VERSION "HSCAN6"

NS_ :

BS_:

BU_: Merged DBC

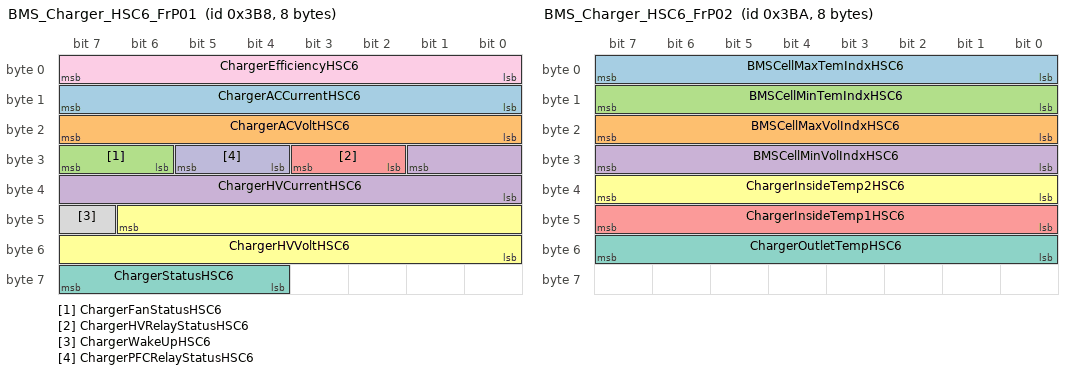
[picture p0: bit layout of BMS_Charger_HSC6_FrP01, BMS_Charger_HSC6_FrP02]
BO_ 952 BMS_Charger_HSC6_FrP01: 8 BMS
 SG_ ChargerACCurrentHSC6 : 15|8@0+ (0.2,0) [0|50.8] "A"  vector__xxx
 SG_ ChargerACVoltHSC6 : 23|8@0+ (2,0) [0|508] "V"  vector__xxx
 SG_ ChargerFanStatusHSC6 : 31|2@0+ (1,0) [0|3] ""  vector__xxx
 SG_ ChargerHVCurrentHSC6 : 25|10@0+ (0.02,0) [0|20.44] "A"  vector__xxx
 SG_ ChargerHVRelayStatusHSC6 : 27|2@0+ (1,0) [0|3] ""  vector__xxx
 SG_ ChargerHVVoltHSC6 : 46|15@0+ (0.02,0) [0|655.32] "V"  vector__xxx
 SG_ ChargerStatusHSC6 : 63|4@0+ (1,0) [0|15] ""  Telematics_BOX
 SG_ ChargerWakeUpHSC6 : 47|1@0+ (1,0) [0|1] ""  vector__xxx
 SG_ ChargerEfficiencyHSC6 : 7|8@0+ (0.5,0) [0|127] "%"  Tester
 SG_ ChargerPFCRelayStatusHSC6 : 29|2@0+ (1,0) [0|3] ""  vector__xxx

BO_ 954 BMS_Charger_HSC6_FrP02: 8 BMS
 SG_ BMSCellMaxTemIndxHSC6 : 7|8@0+ (1,0) [0|254] ""  Telematics_BOX
 SG_ BMSCellMaxVolIndxHSC6 : 23|8@0+ (1,0) [0|254] ""  Telematics_BOX
 SG_ BMSCellMinTemIndxHSC6 : 15|8@0+ (1,0) [0|254] ""  Telematics_BOX
 SG_ BMSCellMinVolIndxHSC6 : 31|8@0+ (1,0) [0|254] ""  Telematics_BOX
 SG_ ChargerInsideTemp1HSC6 : 47|8@0+ (1,-40) [-40|214] "DegC"  vector__xxx
 SG_ ChargerInsideTemp2HSC6 : 39|8@0+ (1,-40) [-40|214] "DegC"  vector__xxx
 SG_ ChargerOutletTempHSC6 : 55|8@0+ (1,-40) [-40|214] "DegC"  vector__xxx

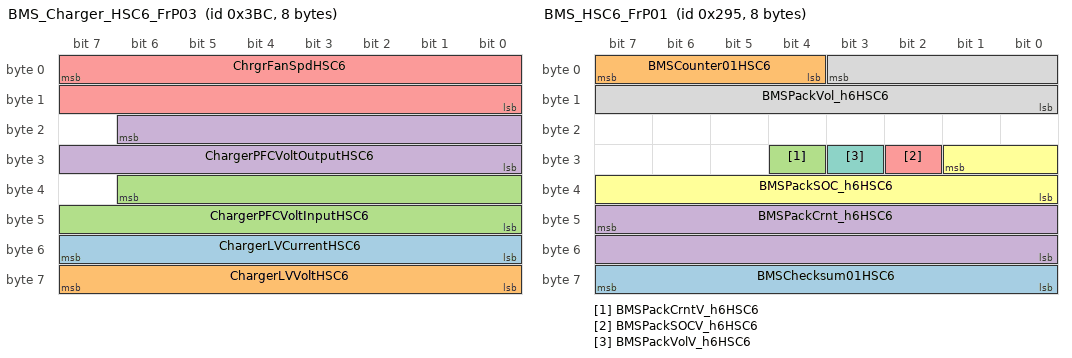
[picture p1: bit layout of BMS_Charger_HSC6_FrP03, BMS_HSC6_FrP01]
BO_ 956 BMS_Charger_HSC6_FrP03: 8 BMS
 SG_ ChargerLVCurrentHSC6 : 55|8@0+ (0.1,0) [0|25.4] "A"  vector__xxx
 SG_ ChargerLVVoltHSC6 : 63|8@0+ (0.1,0) [0|25.4] "V"  vector__xxx
 SG_ ChargerPFCVoltInputHSC6 : 38|15@0+ (0.02,0) [0|655.32] "V"  vector__xxx
 SG_ ChargerPFCVoltOutputHSC6 : 22|15@0+ (0.02,0) [0|655.32] "V"  vector__xxx
 SG_ ChrgrFanSpdHSC6 : 7|16@0+ (1,0) [0|65535] "r/s"  vector__xxx

BO_ 958 BMS_Charger_HSC6_FrP04: 8 BMS
 SG_ BMSCellTemHSC6 : 15|8@0+ (1,-40) [-40|215] "¡æ"  Telematics_BOX
 SG_ BMSCellTemIndxHSC6 : 39|8@0+ (1,0) [0|254] ""  Telematics_BOX
 SG_ BMSCellTemVHSC6 : 7|1@0+ (1,0) [0|1] ""  Telematics_BOX
 SG_ BMSCellVolHSC6 : 19|12@0+ (0.001,1) [1|5.095] "V"  Telematics_BOX
 SG_ BMSCellVolIndxHSC6 : 47|8@0+ (1,0) [0|254] ""  Telematics_BOX
 SG_ BMSCellVolVHSC6 : 6|1@0+ (1,0) [0|1] ""  Telematics_BOX
 SG_ Charger12VUVHSC6 : 5|1@0+ (1,0) [0|1] ""  vector__xxx
 SG_ ChargerBatteryReverseHSC6 : 4|1@0+ (1,0) [0|1] ""  vector__xxx
 SG_ ChargerCANMissingHSC6 : 22|1@0+ (1,0) [0|1] ""  vector__xxx
 SG_ ChargerHVOVHSC6 : 3|1@0+ (1,0) [0|1] ""  vector__xxx
 SG_ ChargerHVUVHSC6 : 2|1@0+ (1,0) [0|1] ""  vector__xxx
 SG_ ChargerInletTempOTPHSC6 : 1|1@0+ (1,0) [0|1] ""  vector__xxx
 SG_ ChargerInsideTemp1OTPHSC6 : 0|1@0+ (1,0) [0|1] ""  vector__xxx
 SG_ ChargerVinUVHSC6 : 23|1@0+ (1,0) [0|1] ""  vector__xxx
 SG_ ChrgrAltCrntLmtHSC6 : 31|8@0+ (0.5,0) [0|127] "A"  vector__xxx
 SG_ ChrgrPriySideStwrOverCHSC6 : 20|1@0+ (1,0) [0|1] ""  vector__xxx

BO_ 659 BMS_HSC6_FrP00: 8 BMS
 SG_ BMSBalancingDoneHSC6 : 18|1@0+ (1,0) [0|1] ""  Tester
 SG_ BMSBalancingStatusHSC6 : 24|1@0+ (1,0) [0|1] ""  Telematics_BOX,Tester
 SG_ BMSCellBalancingCountHSC6 : 15|8@0+ (1,0) [0|253] ""  Tester
 SG_ BMSCellOverVoltHSC6 : 39|1@0+ (1,0) [0|1] ""  Tester
 SG_ BMSCellUnderVoltHSC6 : 19|1@0+ (1,0) [0|1] ""  Tester
 SG_ BMSContactorPowerCmdHSC6 : 16|1@0+ (1,0) [0|1] ""  Tester
 SG_ BMSContactorPowerMonHSC6 : 25|1@0+ (1,0) [0|1] ""  Tester
 SG_ BMSCrashCircuitStatusHSC6 : 17|1@0+ (1,0) [0|1] ""  Tester
 SG_ BMSEEpromWipHSC6 : 38|1@0+ (1,0) [0|1] ""  Tester
 SG_ BMSLVBatInputHSC6 : 7|8@0+ (0.1,0) [0|25.3] "V"  Telematics_BOX,Tester
 SG_ BMSModuleEnableHSC6 : 27|1@0+ (1,0) [0|1] ""  Tester
 SG_ BMSNegRelayStatusHSC6 : 47|2@0+ (1,0) [0|3] ""  Telematics_BOX,Tester
 SG_ BMSOffbdChargerWakeupHSC6 : 30|1@0+ (1,0) [0|1] ""  Tester
 SG_ BMSOnbdChargerWakeupHSC6 : 28|1@0+ (1,0) [0|1] ""  Tester
 SG_ BMSPosRelayStatusHSC6 : 33|2@0+ (1,0) [0|3] ""  Telematics_BOX,Tester
 SG_ BMSPreRelayStatusHSC6 : 35|2@0+ (1,0) [0|3] ""  Telematics_BOX,Tester
 SG_ BMSPTIsolationLevelHSC6 : 37|2@0+ (1,0) [0|3] ""  Tester
 SG_ BMSReadyHSC6 : 26|1@0+ (1,0) [0|1] ""  Tester
 SG_ BMSRelayStepHSC6 : 23|4@0+ (1,0) [0|15] ""  Telematics_BOX,Tester
 SG_ BMSVehicleWakeupHSC6 : 29|1@0+ (1,0) [0|1] ""  Telematics_BOX,Tester
 SG_ BMSChgRelayStatusHSC6 : 45|2@0+ (1,0) [0|3] ""  Tester,Telematics_BOX
 SG_ BMSOffbdChargerPlugOnHSC6 : 31|1@0+ (1,0) [0|1] ""  Tester

BO_ 661 BMS_HSC6_FrP01: 8 BMS
 SG_ BMSChecksum01HSC6 : 63|8@0+ (1,0) [0|0] ""  HCU
 SG_ BMSCounter01HSC6 : 7|4@0+ (1,0) [0|15] "count value"  HCU
 SG_ BMSPackCrntV_h6HSC6 : 28|1@0+ (1,0) [0|1] ""  Telematics_BOX,HCU,TC
 SG_ BMSPackCrnt_h6HSC6 : 47|16@0+ (0.025,-1000) [-1000|638.375] "A"  Telematics_BOX,HCU,TC
 SG_ BMSPackSOCV_h6HSC6 : 26|1@0+ (1,0) [0|1] ""  Telematics_BOX,HCU,TC
 SG_ BMSPackSOC_h6HSC6 : 25|10@0+ (0.1,0) [0|102.3] "%"  Telematics_BOX,HCU,TC
 SG_ BMSPackVolV_h6HSC6 : 27|1@0+ (1,0) [0|1] ""  Telematics_BOX,HCU,TC
 SG_ BMSPackVol_h6HSC6 : 3|12@0+ (0.25,0) [0|1023.75] "V"  Telematics_BOX,HCU,TC

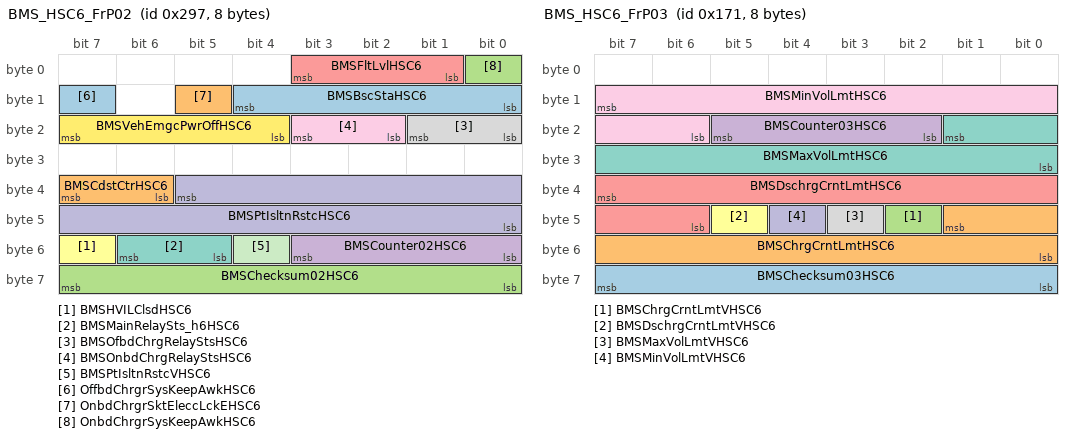
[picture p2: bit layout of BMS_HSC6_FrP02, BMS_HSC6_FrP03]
BO_ 663 BMS_HSC6_FrP02: 8 BMS
 SG_ BMSBscStaHSC6 : 12|5@0+ (1,0) [0|31] ""  Telematics_BOX,HCU,TC
 SG_ BMSCdstCtrHSC6 : 39|2@0+ (1,0) [0|3] ""  Telematics_BOX,HCU
 SG_ BMSChecksum02HSC6 : 63|8@0+ (1,0) [0|0] ""  HCU
 SG_ BMSCounter02HSC6 : 51|4@0+ (1,0) [0|15] "count value"  HCU,TC
 SG_ BMSFltLvlHSC6 : 3|3@0+ (1,0) [0|7] ""  Telematics_BOX,HCU
 SG_ BMSHVILClsdHSC6 : 55|1@0+ (1,0) [0|1] ""  Telematics_BOX,HCU
 SG_ BMSMainRelaySts_h6HSC6 : 54|2@0+ (1,0) [0|3] ""  Telematics_BOX,HCU,TC
 SG_ BMSOfbdChrgRelayStsHSC6 : 17|2@0+ (1,0) [0|3] ""  vector__xxx
 SG_ BMSOnbdChrgRelayStsHSC6 : 19|2@0+ (1,0) [0|3] ""  vector__xxx
 SG_ BMSPtIsltnRstcHSC6 : 37|14@0+ (0.5,0) [0|8191.5] "kOhm"  Telematics_BOX,HCU
 SG_ BMSPtIsltnRstcVHSC6 : 52|1@0+ (1,0) [0|1] ""  Telematics_BOX,HCU
 SG_ BMSVehEmgcPwrOffHSC6 : 23|4@0+ (1,0) [0|15] ""  Tester
 SG_ OffbdChrgrSysKeepAwkHSC6 : 15|1@0+ (1,0) [0|1] ""  Telematics_BOX,HCU
 SG_ OnbdChrgrSktEleccLckEHSC6 : 13|1@0+ (1,0) [0|1] ""  HCU
 SG_ OnbdChrgrSysKeepAwkHSC6 : 0|1@0+ (1,0) [0|1] ""  Telematics_BOX,HCU

BO_ 369 BMS_HSC6_FrP03: 8 BMS
 SG_ BMSChecksum03HSC6 : 63|8@0+ (1,0) [0|0] ""  TC
 SG_ BMSChrgCrntLmtHSC6 : 41|10@0+ (1,-1023) [-1023|0] "A"  HCU,TC
 SG_ BMSChrgCrntLmtVHSC6 : 42|1@0+ (1,0) [0|1] ""  HCU,TC
 SG_ BMSCounter03HSC6 : 21|4@0+ (1,0) [0|15] "count value"  TC
 SG_ BMSDschrgCrntLmtHSC6 : 39|10@0+ (1,0) [0|1023] "A"  HCU,TC
 SG_ BMSDschrgCrntLmtVHSC6 : 45|1@0+ (1,0) [0|1] ""  HCU,TC
 SG_ BMSMaxVolLmtHSC6 : 17|10@0+ (1,0) [0|1023] "V"  TC
 SG_ BMSMaxVolLmtVHSC6 : 43|1@0+ (1,0) [0|1] ""  TC
 SG_ BMSMinVolLmtHSC6 : 15|10@0+ (1,0) [0|1023] "V"  TC
 SG_ BMSMinVolLmtVHSC6 : 44|1@0+ (1,0) [0|1] ""  TC

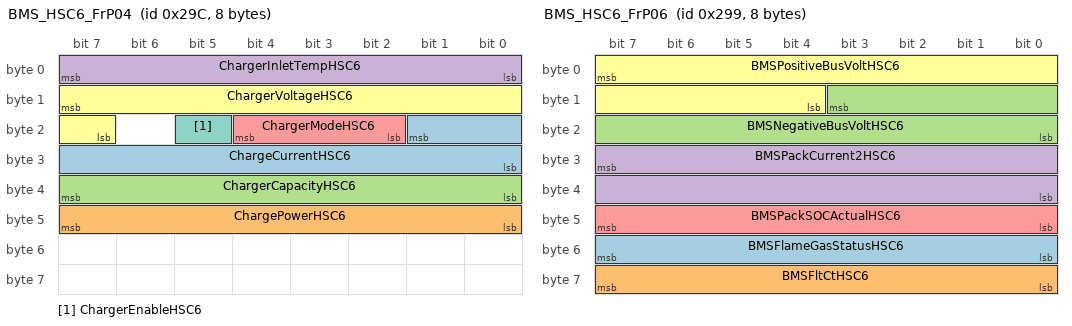
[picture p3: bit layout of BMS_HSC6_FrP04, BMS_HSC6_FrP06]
BO_ 668 BMS_HSC6_FrP04: 8 BMS
 SG_ ChargeCurrentHSC6 : 17|10@0+ (0.02,0) [0|20.44] "fail"  vector__xxx
 SG_ ChargePowerHSC6 : 47|8@0+ (0.05,0) [0|12.7] "kw"  vector__xxx
 SG_ ChargerCapacityHSC6 : 39|8@0+ (1,0) [0|254] "Ah"  vector__xxx
 SG_ ChargerInletTempHSC6 : 7|8@0+ (1,-40) [-40|215] "DegC"  vector__xxx
 SG_ ChargerModeHSC6 : 20|3@0+ (1,0) [0|7] ""  vector__xxx
 SG_ ChargerVoltageHSC6 : 15|9@0+ (1,0) [0|430] ""  Tester
 SG_ ChargerEnableHSC6 : 21|1@0+ (1,0) [0|1] ""  vector__xxx

BO_ 665 BMS_HSC6_FrP06: 8 BMS
 SG_ BMSFlameGasStatusHSC6 : 55|8@0+ (0.5,0) [0|126.5] "%"  Tester
 SG_ BMSFltCtHSC6 : 63|8@0+ (1,0) [0|255] ""  Tester
 SG_ BMSNegativeBusVoltHSC6 : 11|12@0+ (0.25,-500) [-500|523.25] "V"  Tester
 SG_ BMSPackCurrent2HSC6 : 31|16@0+ (0.025,-1000) [-1000|638.325] "A"  Tester
 SG_ BMSPackSOCActualHSC6 : 47|8@0+ (0.5,0) [0|126.5] "%"  Tester
 SG_ BMSPositiveBusVoltHSC6 : 7|12@0+ (0.25,0) [0|1023.25] "V"  Tester

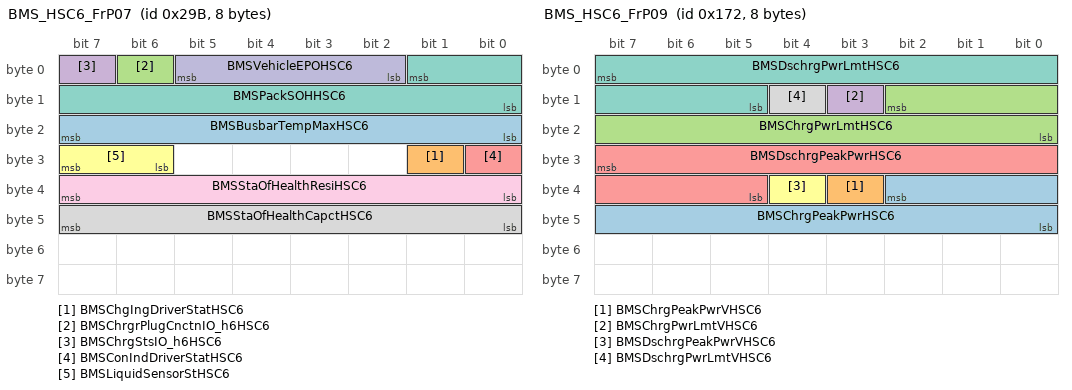
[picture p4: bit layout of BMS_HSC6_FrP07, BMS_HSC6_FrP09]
BO_ 667 BMS_HSC6_FrP07: 8 BMS
 SG_ BMSBusbarTempMaxHSC6 : 23|8@0+ (0.5,-40) [-40|86.5] "DegC"  Tester
 SG_ BMSChgIngDriverStatHSC6 : 25|1@0+ (1,0) [0|1] ""  vector__xxx
 SG_ BMSChrgrPlugCnctnIO_h6HSC6 : 6|1@0+ (1,0) [0|1] ""  Telematics_BOX
 SG_ BMSChrgStsIO_h6HSC6 : 7|1@0+ (1,0) [0|1] ""  Telematics_BOX
 SG_ BMSConIndDriverStatHSC6 : 24|1@0+ (1,0) [0|1] ""  Tester
 SG_ BMSLiquidSensorStHSC6 : 31|2@0+ (1,0) [0|3] ""  Tester
 SG_ BMSPackSOHHSC6 : 1|10@0+ (0.1,0) [0|102.1] "%"  Tester
 SG_ BMSStaOfHealthCapctHSC6 : 47|8@0+ (0.5,0) [0|126.5] "%"  Tester
 SG_ BMSStaOfHealthResiHSC6 : 39|8@0+ (0.5,0) [0|126.5] "%"  Tester
 SG_ BMSVehicleEPOHSC6 : 5|4@0+ (1,0) [0|15] ""  Tester

BO_ 1100 BMS_HSC6_FrP08: 1 BMS
 SG_ keep_network_BMSHSC6 : 0|1@0+ (1,0) [0|1] ""  Telematics_BOX
 SG_ keep_network_BMSHSC6_UB : 1|1@0+ (1,0) [0|1] ""  Telematics_BOX

BO_ 370 BMS_HSC6_FrP09: 8 BMS
 SG_ BMSChrgPeakPwrHSC6 : 34|11@0+ (0.1,0) [0|204.7] "kw"  HCU
 SG_ BMSChrgPeakPwrVHSC6 : 35|1@0+ (1,0) [0|1] ""  HCU
 SG_ BMSChrgPwrLmtHSC6 : 10|11@0+ (0.1,0) [0|204.7] "kw"  HCU
 SG_ BMSChrgPwrLmtVHSC6 : 11|1@0+ (1,0) [0|1] ""  HCU
 SG_ BMSDschrgPeakPwrHSC6 : 31|11@0+ (0.1,0) [0|204.7] "kw"  HCU
 SG_ BMSDschrgPeakPwrVHSC6 : 36|1@0+ (1,0) [0|1] ""  HCU
 SG_ BMSDschrgPwrLmtHSC6 : 7|11@0+ (0.1,0) [0|204.7] "kw"  HCU
 SG_ BMSDschrgPwrLmtVHSC6 : 12|1@0+ (1,0) [0|1] ""  HCU

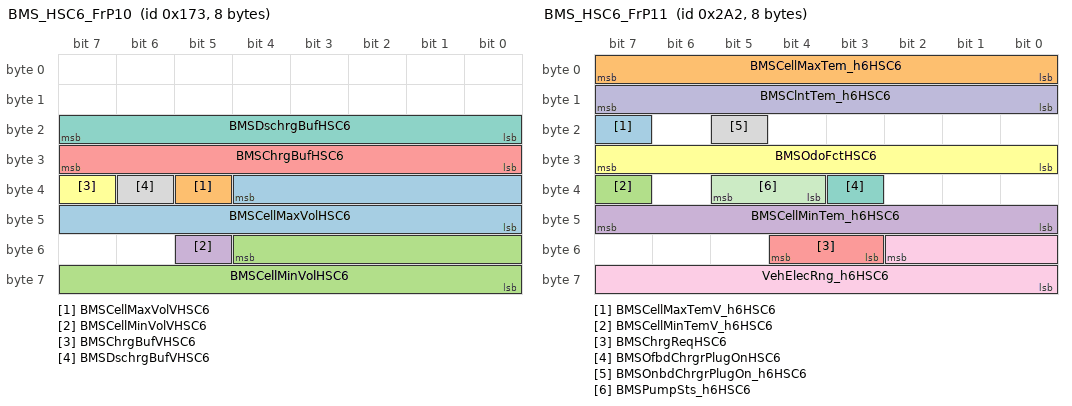
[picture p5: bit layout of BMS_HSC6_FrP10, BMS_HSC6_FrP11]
BO_ 371 BMS_HSC6_FrP10: 8 BMS
 SG_ BMSCellMaxVolHSC6 : 36|13@0+ (0.001,0) [0|8.191] "V"  Telematics_BOX
 SG_ BMSCellMaxVolVHSC6 : 37|1@0+ (1,0) [0|1] ""  Telematics_BOX,Tester
 SG_ BMSCellMinVolHSC6 : 52|13@0+ (0.001,0) [0|8.191] "V"  Telematics_BOX
 SG_ BMSCellMinVolVHSC6 : 53|1@0+ (1,0) [0|1] ""  Telematics_BOX,Tester
 SG_ BMSChrgBufHSC6 : 31|8@0+ (0.5,0) [0|127.5] "%"  HCU
 SG_ BMSChrgBufVHSC6 : 39|1@0+ (1,0) [0|1] ""  HCU
 SG_ BMSDschrgBufHSC6 : 23|8@0+ (0.5,0) [0|127.5] "%"  HCU
 SG_ BMSDschrgBufVHSC6 : 38|1@0+ (1,0) [0|1] ""  HCU

BO_ 674 BMS_HSC6_FrP11: 8 BMS
 SG_ BMSCellMaxTemV_h6HSC6 : 23|1@0+ (1,0) [0|1] ""  Telematics_BOX,Tester
 SG_ BMSCellMaxTem_h6HSC6 : 7|8@0+ (0.5,-40) [-40|87.5] "DegC"  Telematics_BOX,Tester
 SG_ BMSCellMinTemV_h6HSC6 : 39|1@0+ (1,0) [0|1] ""  Telematics_BOX,Tester
 SG_ BMSCellMinTem_h6HSC6 : 47|8@0+ (0.5,-40) [-40|87.5] "Deg C"  Telematics_BOX,Tester
 SG_ BMSChrgReqHSC6 : 52|2@0+ (1,0) [0|3] ""  HCU
 SG_ BMSOdoFctHSC6 : 31|8@0+ (0.5,0) [0|127.5] "%"  Tester
 SG_ BMSOfbdChrgrPlugOnHSC6 : 35|1@0+ (1,0) [0|1] ""  HCU
 SG_ BMSOnbdChrgrPlugOn_h6HSC6 : 21|1@0+ (1,0) [0|1] ""  Telematics_BOX
 SG_ VehElecRng_h6HSC6 : 50|11@0+ (1,0) [0|2047] "km"  Telematics_BOX
 SG_ BMSClntTem_h6HSC6 : 15|8@0+ (0.5,-40) [-40|87.5] "degC"  vector__xxx
 SG_ BMSPumpSts_h6HSC6 : 37|2@0+ (1,0) [0|3] ""  Telematics_BOX

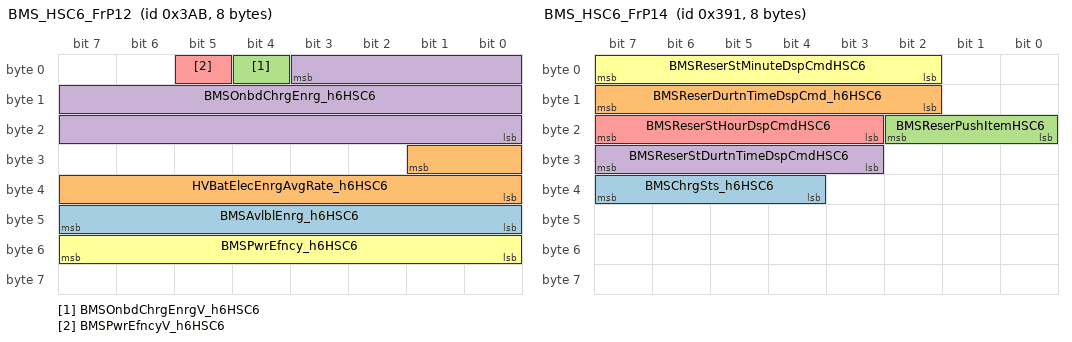
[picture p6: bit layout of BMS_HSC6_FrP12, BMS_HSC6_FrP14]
BO_ 939 BMS_HSC6_FrP12: 8 BMS
 SG_ BMSAvlblEnrg_h6HSC6 : 47|8@0+ (0.1,0) [0|25.5] "kWh"  Telematics_BOX
 SG_ HVBatElecEnrgAvgRate_h6HSC6 : 25|10@0+ (0.1,-20) [-20|82.3] ""  Telematics_BOX
 SG_ BMSOnbdChrgEnrgV_h6HSC6 : 4|1@0+ (1,0) [0|1] ""  Tester
 SG_ BMSOnbdChrgEnrg_h6HSC6 : 3|20@0+ (0.1,0) [0|104857] ""  Tester
 SG_ BMSPwrEfncyV_h6HSC6 : 5|1@0+ (1,0) [0|1] ""  vector__xxx
 SG_ BMSPwrEfncy_h6HSC6 : 55|8@0+ (0.5,0) [0|126.5] ""  Tester

BO_ 940 BMS_HSC6_FrP13: 8 BMS
 SG_ BMSPackSOCDsp_h6HSC6 : 17|10@0+ (0.1,0) [0|102.3] ""  Telematics_BOX

BO_ 913 BMS_HSC6_FrP14: 8 BMS
 SG_ BMSChrgSts_h6HSC6 : 39|4@0+ (1,0) [0|15] ""  Telematics_BOX
 SG_ BMSReserDurtnTimeDspCmd_h6HSC6 : 15|6@0+ (0.5,0) [0|20] ""  Telematics_BOX
 SG_ BMSReserPushItemHSC6 : 18|3@0+ (1,0) [0|7] ""  Telematics_BOX
 SG_ BMSReserStDurtnTimeDspCmdHSC6 : 31|5@0+ (1,0) [0|23] ""  Telematics_BOX
 SG_ BMSReserStHourDspCmdHSC6 : 23|5@0+ (1,0) [0|31] ""  Telematics_BOX
 SG_ BMSReserStMinuteDspCmdHSC6 : 7|6@0+ (1,0) [0|63] ""  Telematics_BOX

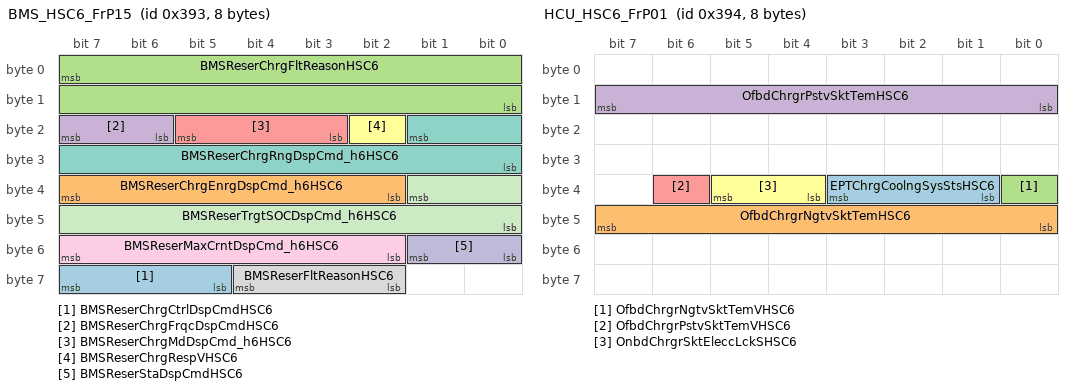
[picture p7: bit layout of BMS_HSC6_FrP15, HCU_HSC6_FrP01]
BO_ 915 BMS_HSC6_FrP15: 8 BMS
 SG_ BMSReserChrgCtrlDspCmdHSC6 : 63|3@0+ (1,0) [0|7] ""  Telematics_BOX
 SG_ BMSReserChrgEnrgDspCmd_h6HSC6 : 39|6@0+ (1,0) [0|63] ""  Telematics_BOX
 SG_ BMSReserChrgFltReasonHSC6 : 7|16@0+ (1,0) [0|65535] ""  Telematics_BOX
 SG_ BMSReserChrgFrqcDspCmdHSC6 : 23|2@0+ (1,0) [0|3] ""  Telematics_BOX
 SG_ BMSReserChrgMdDspCmd_h6HSC6 : 21|3@0+ (1,0) [0|7] ""  Telematics_BOX
 SG_ BMSReserChrgRespVHSC6 : 18|1@0+ (1,0) [0|1] ""  Telematics_BOX
 SG_ BMSReserChrgRngDspCmd_h6HSC6 : 17|10@0+ (1,0) [0|1023] ""  Telematics_BOX
 SG_ BMSReserFltReasonHSC6 : 60|3@0+ (1,0) [0|7] ""  Telematics_BOX
 SG_ BMSReserMaxCrntDspCmd_h6HSC6 : 55|6@0+ (1,0) [0|32] ""  Telematics_BOX
 SG_ BMSReserStaDspCmdHSC6 : 49|2@0+ (1,0) [0|3] ""  Telematics_BOX
 SG_ BMSReserTrgtSOCDspCmd_h6HSC6 : 33|10@0+ (0.1,0) [0|102.3] ""  Telematics_BOX

BO_ 936 BMS_HSC6_FrP16: 8 BMS
 SG_ ChrgngRmnngTimeV_h6HSC6 : 54|1@0+ (1,0) [0|1] ""  Telematics_BOX
 SG_ ChrgngRmnngTime_h6HSC6 : 31|10@0+ (1,0) [0|1023] "minute"  Telematics_BOX

BO_ 1091 BMS_HSC6_FrS00: 1 BMS
 SG_ wake_network_BMSHSC6 : 0|1@0+ (1,0) [0|1] ""  Telematics_BOX
 SG_ wake_network_BMSHSC6_UB : 1|1@0+ (1,0) [0|1] ""  Telematics_BOX

BO_ 916 HCU_HSC6_FrP01: 8 HCU
 SG_ EPTChrgCoolngSysStsHSC6 : 35|3@0+ (1,0) [0|7] ""  BMS
 SG_ OfbdChrgrNgtvSktTemHSC6 : 47|8@0+ (1,-40) [-40|215] "¡æ"  BMS
 SG_ OfbdChrgrNgtvSktTemVHSC6 : 32|1@0+ (1,0) [0|1] ""  BMS
 SG_ OfbdChrgrPstvSktTemHSC6 : 15|8@0+ (1,-40) [-40|215] "¡æ"  BMS
 SG_ OfbdChrgrPstvSktTemVHSC6 : 38|1@0+ (1,0) [0|1] ""  BMS
 SG_ OnbdChrgrSktEleccLckSHSC6 : 37|2@0+ (1,0) [0|3] ""  BMS

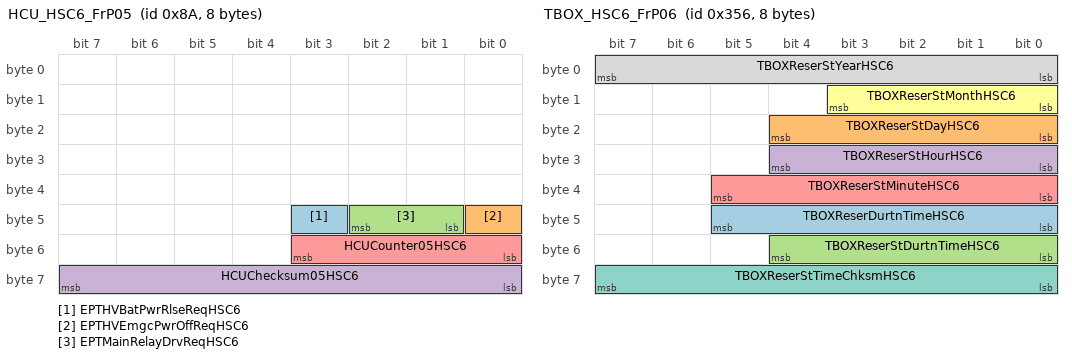
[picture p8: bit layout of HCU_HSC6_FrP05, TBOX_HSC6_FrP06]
BO_ 138 HCU_HSC6_FrP05: 8 HCU
 SG_ EPTHVBatPwrRlseReqHSC6 : 43|1@0+ (1,0) [0|1] ""  BMS
 SG_ EPTHVEmgcPwrOffReqHSC6 : 40|1@0+ (1,0) [0|1] ""  BMS
 SG_ EPTMainRelayDrvReqHSC6 : 42|2@0+ (1,0) [0|3] ""  BMS
 SG_ HCUChecksum05HSC6 : 63|8@0+ (1,0) [0|255] ""  BMS
 SG_ HCUCounter05HSC6 : 51|4@0+ (1,0) [0|15] ""  BMS

BO_ 854 TBOX_HSC6_FrP06: 8 Telematics_BOX
 SG_ TBOXReserDurtnTimeHSC6 : 45|6@0+ (0.5,0) [0|20] ""  BMS
 SG_ TBOXReserStDayHSC6 : 20|5@0+ (1,0) [0|31] ""  BMS
 SG_ TBOXReserStDurtnTimeHSC6 : 52|5@0+ (1,0) [0|23] ""  BMS
 SG_ TBOXReserStHourHSC6 : 28|5@0+ (1,0) [0|31] ""  BMS
 SG_ TBOXReserStMinuteHSC6 : 37|6@0+ (1,0) [0|63] ""  BMS
 SG_ TBOXReserStMonthHSC6 : 11|4@0+ (1,0) [0|15] ""  BMS
 SG_ TBOXReserStTimeChksmHSC6 : 63|8@0+ (1,0) [0|255] ""  BMS
 SG_ TBOXReserStYearHSC6 : 7|8@0+ (1,2000) [2000|2255] ""  BMS

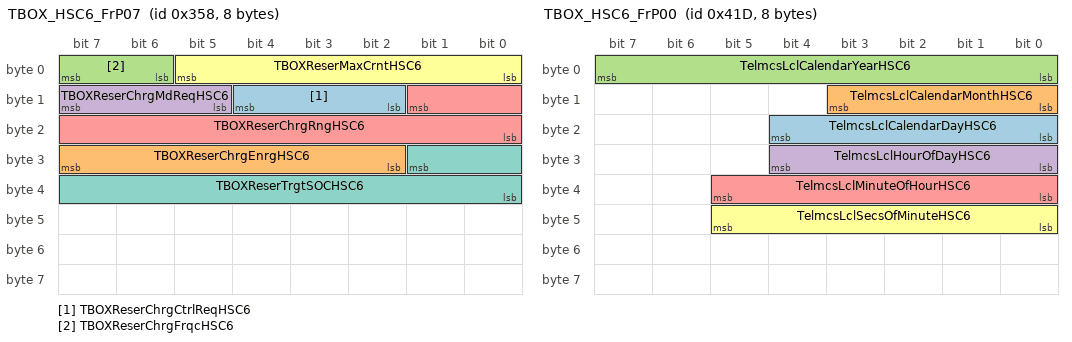
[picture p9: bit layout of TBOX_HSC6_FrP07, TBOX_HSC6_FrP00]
BO_ 856 TBOX_HSC6_FrP07: 8 Telematics_BOX
 SG_ TBOXReserChrgCtrlReqHSC6 : 12|3@0+ (1,0) [0|7] ""  BMS
 SG_ TBOXReserChrgEnrgHSC6 : 31|6@0+ (1,0) [0|63] ""  BMS
 SG_ TBOXReserChrgFrqcHSC6 : 7|2@0+ (1,0) [0|3] ""  BMS
 SG_ TBOXReserChrgMdReqHSC6 : 15|3@0+ (1,0) [0|7] ""  BMS
 SG_ TBOXReserChrgRngHSC6 : 9|10@0+ (1,0) [0|1023] ""  BMS
 SG_ TBOXReserMaxCrntHSC6 : 5|6@0+ (1,0) [0|32] ""  BMS
 SG_ TBOXReserTrgtSOCHSC6 : 25|10@0+ (0.1,0) [0|102.3] ""  BMS

BO_ 1055 TBOX_HSC6_NWM: 3 Telematics_BOX
 SG_ network_mode_h6 : 23|8@0+ (1,0) [0|255] ""  BMS
 SG_ signal_config_id_h6 : 7|16@0+ (1,0) [0|65535] ""  BMS

BO_ 153 TC_HSC6_FrP02: 8 TC
 SG_ TMInvtrCrntHSC6 : 23|11@0+ (1,-1024) [-1024|1023] "A"  BMS
 SG_ TMInvtrCrntVHSC6 : 28|1@0+ (1,0) [0|1] ""  BMS

BO_ 331 TC_HSC6_FrP08: 8 TC
 SG_ TMInvtrVolHSC6 : 1|10@0+ (1,0) [0|1021] ""  BMS
 SG_ TMInvtrVolVHSC6 : 2|1@0+ (1,0) [0|1] ""  BMS

BO_ 930 HVDCDC_HSC6_FrP01: 8 ISC
 SG_ HVDCDCHVSideVolHSC6 : 15|10@0+ (1,0) [0|1023] "V"  BMS
 SG_ HVDCDCHVSideVolVHSC6 : 18|1@0+ (1,0) [0|1] ""  BMS

BO_ 150 ISC_HSC6_FrP04: 8 ISC
 SG_ ISGInvtrCrntHSC6 : 7|11@0+ (1,-1024) [-1024|1023] "A"  BMS
 SG_ ISGInvtrCrntVHSC6 : 12|1@0+ (1,0) [0|1] ""  BMS

BO_ 1053 TBOX_HSC6_FrP00: 8 Telematics_BOX
 SG_ TelmcsLclCalendarDayHSC6 : 20|5@0+ (1,0) [0|31] ""  BMS
 SG_ TelmcsLclCalendarMonthHSC6 : 11|4@0+ (1,0) [0|15] ""  BMS
 SG_ TelmcsLclCalendarYearHSC6 : 7|8@0+ (1,2000) [2000|2255] ""  BMS
 SG_ TelmcsLclHourOfDayHSC6 : 28|5@0+ (1,0) [0|23] ""  BMS
 SG_ TelmcsLclMinuteOfHourHSC6 : 37|6@0+ (1,0) [0|59] ""  BMS
 SG_ TelmcsLclSecsOfMinuteHSC6 : 45|6@0+ (1,0) [0|59] ""  BMS

CM_ SG_ 952 ChargerACCurrentHSC6 "current at charger AC side";
CM_ SG_ 952 ChargerACVoltHSC6 "voltage at charger AC side";
CM_ SG_ 952 ChargerFanStatusHSC6 "Charger Cooling Fan Status";
CM_ SG_ 952 ChargerHVRelayStatusHSC6 "Charger HV Relay Status";
CM_ SG_ 952 ChargerStatusHSC6 "charger status";
CM_ SG_ 952 ChargerWakeUpHSC6 "Charger  Wake up";
CM_ SG_ 954 BMSCellMaxTemIndxHSC6 "Battery Management System Cell Maximum Temperature Index";
CM_ SG_ 954 BMSCellMaxVolIndxHSC6 "Battery Management System Cell Maximum Voltage Index";
CM_ SG_ 954 BMSCellMinTemIndxHSC6 "Battery Management System Cell Minimum Temperature Index";
CM_ SG_ 954 BMSCellMinVolIndxHSC6 "Battery Management System Cell Minimum Voltage Index";
CM_ SG_ 956 ChargerLVCurrentHSC6 "current at charger LV side";
CM_ SG_ 958 BMSCellTemHSC6 "Battery Management System Cell Temperature";
CM_ SG_ 958 BMSCellTemIndxHSC6 "Battery Management System Cell Temperature Index";
CM_ SG_ 958 BMSCellTemVHSC6 "Battery Management System Cell Temperature Validity";
CM_ SG_ 958 BMSCellVolHSC6 "Battery Management System Cell Voltage";
CM_ SG_ 958 BMSCellVolIndxHSC6 "Battery Management System Cell Voltage Index";
CM_ SG_ 958 BMSCellVolVHSC6 "Battery Management System Cell Voltage Validity";
CM_ SG_ 659 BMSCellOverVoltHSC6 "one or more cells are above normal voltage range";
CM_ SG_ 659 BMSCellUnderVoltHSC6 "One or more cells are below normal voltage range";
CM_ SG_ 659 BMSContactorPowerCmdHSC6 "contactor Power Relay command state";
CM_ SG_ 659 BMSContactorPowerMonHSC6 "contactor Power Relay monitor";
CM_ SG_ 659 BMSCrashCircuitStatusHSC6 "crash switch circuit status";
CM_ SG_ 659 BMSEEpromWipHSC6 "BMS fault status: EEPROM write in progress";
CM_ SG_ 659 BMSLVBatInputHSC6 "LV Battery Voltage";
CM_ SG_ 659 BMSNegRelayStatusHSC6 "Main negtive contactor status";
CM_ SG_ 659 BMSOffbdChargerWakeupHSC6 "Offboard charger wakeup monitor";
CM_ SG_ 659 BMSOnbdChargerWakeupHSC6 "Onboard charger wakeup monitor";
CM_ SG_ 659 BMSPosRelayStatusHSC6 "Main positive contactor status";
CM_ SG_ 659 BMSPreRelayStatusHSC6 "Pre-charge contactor status";
CM_ SG_ 659 BMSPTIsolationLevelHSC6 "BMS PT Isolation Level";
CM_ SG_ 659 BMSReadyHSC6 "BMS completed Power On Self Test ";
CM_ SG_ 659 BMSRelayStepHSC6 "bms  relays step";
CM_ SG_ 659 BMSVehicleWakeupHSC6 "vehicle wakeup monitor";
CM_ SG_ 661 BMSChecksum01HSC6 "BMS FrP01 checksum";
CM_ SG_ 661 BMSCounter01HSC6 "BMS FrP01 rolling counter";
CM_ SG_ 661 BMSPackCrntV_h6HSC6 "Battery Management System Pack Current Validity";
CM_ SG_ 661 BMSPackCrnt_h6HSC6 "Battery Management System Pack Current";
CM_ SG_ 661 BMSPackSOCV_h6HSC6 "Battery Management System Pack State Of Charge Validity";
CM_ SG_ 661 BMSPackSOC_h6HSC6 "Battery Management System Pack State Of Charge";
CM_ SG_ 661 BMSPackVolV_h6HSC6 "Battery Management System Pack Voltage Validity";
CM_ SG_ 661 BMSPackVol_h6HSC6 "Battery Management System Pack Voltage";
CM_ SG_ 663 BMSBscStaHSC6 "Battery Management System Basic State";
CM_ SG_ 663 BMSCdstCtrHSC6 "Battery Management System Coldstart Counter";
CM_ SG_ 663 BMSChecksum02HSC6 "BMS FrP02 checksum";
CM_ SG_ 663 BMSCounter02HSC6 "BMS FrP02 rolling counter";
CM_ SG_ 663 BMSFltLvlHSC6 "Battery Management System Fault Level";
CM_ SG_ 663 BMSHVILClsdHSC6 "Battery Management System High Voltage Interlock Loop Closed";
CM_ SG_ 663 BMSMainRelaySts_h6HSC6 "Battery Management System Main Relay Status";
CM_ SG_ 663 BMSPtIsltnRstcHSC6 "Battery Management System Powertrain Isolation Resistance";
CM_ SG_ 663 BMSPtIsltnRstcVHSC6 "Battery Management System Powertrain Isolation Resistance Validity";
CM_ SG_ 663 OffbdChrgrSysKeepAwkHSC6 "Offboard Charger System Keep Awake";
CM_ SG_ 663 OnbdChrgrSysKeepAwkHSC6 "Onboard Charger System Keep Awake";
CM_ SG_ 369 BMSChecksum03HSC6 "BMS FrP03 checksum";
CM_ SG_ 369 BMSChrgCrntLmtHSC6 "Battery Management System Charge Current Limit";
CM_ SG_ 369 BMSChrgCrntLmtVHSC6 "Battery Management System Charge Current Limit Validity";
CM_ SG_ 369 BMSCounter03HSC6 "BMS FrP03 rolling counter";
CM_ SG_ 369 BMSDschrgCrntLmtHSC6 "Battery Management System Discharge Current Limit";
CM_ SG_ 369 BMSDschrgCrntLmtVHSC6 "Battery Management System Discharge Current Limit Validity";
CM_ SG_ 369 BMSMaxVolLmtHSC6 "Battery Management System Maximum Voltage Limit";
CM_ SG_ 369 BMSMaxVolLmtVHSC6 "Battery Management System Maximum Voltage Limit Validity";
CM_ SG_ 369 BMSMinVolLmtHSC6 "Battery Management System Minimum Voltage Limit";
CM_ SG_ 369 BMSMinVolLmtVHSC6 "Battery Management System Minimum Voltage Limit Validity";
CM_ SG_ 668 ChargeCurrentHSC6 "charging current setpoint";
CM_ SG_ 668 ChargePowerHSC6 "charging power setpoint";
CM_ SG_ 668 ChargerCapacityHSC6 "charging capacity setpoint";
CM_ SG_ 668 ChargerInletTempHSC6 "inlet air temperature";
CM_ SG_ 668 ChargerModeHSC6 "charger charging mode request";
CM_ SG_ 668 ChargerVoltageHSC6 "charging voltage setpoint";
CM_ SG_ 665 BMSFlameGasStatusHSC6 "flammable gas detector duty cycle";
CM_ SG_ 665 BMSFltCtHSC6 "BMSFaultCount";
CM_ SG_ 665 BMSNegativeBusVoltHSC6 "HV negative bus voltage ";
CM_ SG_ 665 BMSPackSOCActualHSC6 "bms actual soc....";
CM_ SG_ 665 BMSPositiveBusVoltHSC6 "HV positive bus  voltage";
CM_ SG_ 667 BMSChrgrPlugCnctnIO_h6HSC6 "Battery Management System Charger Plug Connection Indication On";
CM_ SG_ 667 BMSChrgStsIO_h6HSC6 "Battery Management System Charge Status Indication On";
CM_ SG_ 667 BMSLiquidSensorStHSC6 "Liquid level sensor status";
CM_ SG_ 667 BMSPackSOHHSC6 "Battery pack SOH";
CM_ SG_ 667 BMSStaOfHealthCapctHSC6 "Capacity state of health";
CM_ SG_ 667 BMSStaOfHealthResiHSC6 "Resistance state of health";
CM_ SG_ 370 BMSChrgPeakPwrHSC6 "Battery Management System Charge Peak Power";
CM_ SG_ 370 BMSChrgPeakPwrVHSC6 "Battery Management System Charge Peak Power Validity";
CM_ SG_ 370 BMSChrgPwrLmtHSC6 "Battery Management System Charge Power Limit";
CM_ SG_ 370 BMSChrgPwrLmtVHSC6 "Battery Management System Charge Power Limit Validity";
CM_ SG_ 370 BMSDschrgPeakPwrHSC6 "Battery Management System Discharge Peak Power";
CM_ SG_ 370 BMSDschrgPeakPwrVHSC6 "Battery Management System Discharge Peak Power Validity";
CM_ SG_ 370 BMSDschrgPwrLmtHSC6 "Battery Management System Discharge Power Limit";
CM_ SG_ 370 BMSDschrgPwrLmtVHSC6 "Battery Management System Discharge Power Limit Validity";
CM_ SG_ 371 BMSCellMaxVolHSC6 "Battery Management System Cell Maximum Voltage";
CM_ SG_ 371 BMSCellMaxVolVHSC6 "Battery Management System Cell Maximum Voltage Validity";
CM_ SG_ 371 BMSCellMinVolHSC6 "Battery Management System Cell Minimum Voltage";
CM_ SG_ 371 BMSCellMinVolVHSC6 "Battery Management System Cell Minimum Voltage Validity";
CM_ SG_ 371 BMSChrgBufHSC6 "Battery Management System Charge Buffer";
CM_ SG_ 371 BMSChrgBufVHSC6 "Battery Management System Charge Buffer Validity";
CM_ SG_ 371 BMSDschrgBufHSC6 "Battery Management System Discharge Buffer";
CM_ SG_ 371 BMSDschrgBufVHSC6 "Battery Management System Discharge Buffer Validity";
CM_ SG_ 674 BMSCellMaxTemV_h6HSC6 "Battery Management System Cell Maximum Temperature Validity";
CM_ SG_ 674 BMSCellMaxTem_h6HSC6 "Battery Management System Cell Maximum Temperature";
CM_ SG_ 674 BMSCellMinTemV_h6HSC6 "Battery Management System Cell Minimum Temperature Validity";
CM_ SG_ 674 BMSCellMinTem_h6HSC6 "Battery Management System Cell Minimum Temperature";
CM_ SG_ 674 BMSChrgReqHSC6 "Battery Management System Charge Request";
CM_ SG_ 674 BMSOdoFctHSC6 "Battery Management System Odometer Factor";
CM_ SG_ 674 BMSOnbdChrgrPlugOn_h6HSC6 "Battery Management System Onboard Charger Plug On";
CM_ SG_ 674 VehElecRng_h6HSC6 "Vehicle Electric Range";
CM_ SG_ 939 BMSAvlblEnrg_h6HSC6 "Battery Management System Available Energy";
CM_ SG_ 939 HVBatElecEnrgAvgRate_h6HSC6 "High Voltage Battery Electric Energy Average Rate";
CM_ SG_ 940 BMSPackSOCDsp_h6HSC6 "SOC displayed for customer";
CM_ SG_ 913 BMSChrgSts_h6HSC6 "Battery Management System Charge Status";
CM_ SG_ 913 BMSReserDurtnTimeDspCmd_h6HSC6 "Battery Management System Reservation Duration Time Display Command";
CM_ SG_ 913 BMSReserPushItemHSC6 "Battery Management System Reservation Push Items";
CM_ SG_ 913 BMSReserStDurtnTimeDspCmdHSC6 "Battery Management System Reservation Start Duration Time Display Command";
CM_ SG_ 913 BMSReserStHourDspCmdHSC6 "Battery Management System Reservation Start Hour Display Command";
CM_ SG_ 913 BMSReserStMinuteDspCmdHSC6 "Battery Management System Reservation Start Minute Display Command";
CM_ SG_ 915 BMSReserChrgCtrlDspCmdHSC6 "Battery Management System Reservation Charge Control Display Command";
CM_ SG_ 915 BMSReserChrgEnrgDspCmd_h6HSC6 "Battery Management System Reservation Charge Energy Display Command";
CM_ SG_ 915 BMSReserChrgFltReasonHSC6 "Battery Management System Reservation Charge Fault Reason";
CM_ SG_ 915 BMSReserChrgFrqcDspCmdHSC6 "Battery Management System Reservation Charge Frequency Display Command";
CM_ SG_ 915 BMSReserChrgMdDspCmd_h6HSC6 "Battery Management System Reservation Charge Mode Display Command";
CM_ SG_ 915 BMSReserChrgRespVHSC6 "Battery Management System Reservation Charge Response Validity";
CM_ SG_ 915 BMSReserChrgRngDspCmd_h6HSC6 "Battery Management System Reservation Charge Range Display Command";
CM_ SG_ 915 BMSReserFltReasonHSC6 "Battery Management System Reservation Fault Reason";
CM_ SG_ 915 BMSReserMaxCrntDspCmd_h6HSC6 "Battery Management System Reservation Maximun Current Display Command";
CM_ SG_ 915 BMSReserStaDspCmdHSC6 "Battery Management System Reservation State Display Command";
CM_ SG_ 915 BMSReserTrgtSOCDspCmd_h6HSC6 "Battery Management System Reservaion Target Soc Display Command";
CM_ SG_ 936 ChrgngRmnngTimeV_h6HSC6 "Charging Remaining Time Validity";
CM_ SG_ 936 ChrgngRmnngTime_h6HSC6 "Charging Remaining Time";
CM_ SG_ 916 EPTChrgCoolngSysStsHSC6 "Electric Powertrain Charge Cooling system Status";
CM_ SG_ 916 OfbdChrgrNgtvSktTemHSC6 "Offboard Charger Positive Socket Temperature";
CM_ SG_ 916 OfbdChrgrNgtvSktTemVHSC6 "Offboard Charger Positive Socket Temperature";
CM_ SG_ 916 OfbdChrgrPstvSktTemHSC6 "Offboard Charger Positive Socket Temperature";
CM_ SG_ 916 OfbdChrgrPstvSktTemVHSC6 "Offboard Charger Positive Socket Temperature Valid";
CM_ SG_ 138 EPTHVBatPwrRlseReqHSC6 "Electric Powertrain High Voltage Battery Power Release Request";
CM_ SG_ 138 EPTHVEmgcPwrOffReqHSC6 "Electric Powertrain High Voltage Emergency Power Off Request";
CM_ SG_ 138 EPTMainRelayDrvReqHSC6 "Electric Powertrain Main Relay Drive Request";
CM_ SG_ 138 HCUChecksum05HSC6 "HCU FrP05 message Checksum";
CM_ SG_ 138 HCUCounter05HSC6 "HCU FrP05 message Rolling Counter";
CM_ SG_ 854 TBOXReserDurtnTimeHSC6 "Telematics Box Reservation Duration Time";
CM_ SG_ 854 TBOXReserStDayHSC6 "Telematics Box Reservation Charge Start Day";
CM_ SG_ 854 TBOXReserStDurtnTimeHSC6 "Telematics Box Reservation Start Duration Time";
CM_ SG_ 854 TBOXReserStHourHSC6 "Telematics Box Reservation Start Hour";
CM_ SG_ 854 TBOXReserStMinuteHSC6 "Telematics Box Reservation Start Minute";
CM_ SG_ 854 TBOXReserStMonthHSC6 "Telematics Box Reservation Start Month";
CM_ SG_ 854 TBOXReserStTimeChksmHSC6 "Telematics Box Reservation Start Time Checksum";
CM_ SG_ 854 TBOXReserStYearHSC6 "Telematics Box Reservation Start Year";
CM_ SG_ 856 TBOXReserChrgCtrlReqHSC6 "Telematics Box Reservation Charge Control Request";
CM_ SG_ 856 TBOXReserChrgEnrgHSC6 "Telematics Box Reservation Charge Energy";
CM_ SG_ 856 TBOXReserChrgFrqcHSC6 "Telematics Box Reservation Charge Frequency";
CM_ SG_ 856 TBOXReserChrgMdReqHSC6 "Telematics Box Reservation Charge Mode Request";
CM_ SG_ 856 TBOXReserChrgRngHSC6 "Telematics Box Reservation Charge Range";
CM_ SG_ 856 TBOXReserMaxCrntHSC6 "Tbox Reservation Maximun Current";
CM_ SG_ 856 TBOXReserTrgtSOCHSC6 "Telematics Box Reservation Target Soc";
CM_ SG_ 1055 network_mode_h6 "NM signal: this signal contains the intended mode of the network. This signal controls the frame mode used by the slave nodes";
CM_ SG_ 1055 signal_config_id_h6 "NM signal: this is the identification number of the signal configuration used. Read by the slave nodes to determine if they have the correct configuration or not";
CM_ SG_ 153 TMInvtrCrntHSC6 "Traction Motor Inverter Current";
CM_ SG_ 153 TMInvtrCrntVHSC6 "Traction Motor Inverter Current Validity";
CM_ SG_ 331 TMInvtrVolHSC6 "Traction Motor Inverter Voltage";
CM_ SG_ 952 ChargerEfficiencyHSC6 "Charger total Efficiency";
CM_ SG_ 952 ChargerPFCRelayStatusHSC6 "Charger PFC Relay Status";
CM_ SG_ 954 ChargerInsideTemp1HSC6 "charger internal temperature point 1";
CM_ SG_ 954 ChargerInsideTemp2HSC6 "charger internal temperature point 2";
CM_ SG_ 954 ChargerOutletTempHSC6 "outlet air temperature";
CM_ SG_ 956 ChargerPFCVoltInputHSC6 "Charger PFC Volt Input";
CM_ SG_ 956 ChargerPFCVoltOutputHSC6 "Charger PFC Volt Output";
CM_ SG_ 956 ChrgrFanSpdHSC6 "Charger Fan Speed";
CM_ SG_ 958 Charger12VUVHSC6 "The charger output voltage at charger LV side is undervoltage status";
CM_ SG_ 958 ChargerCANMissingHSC6 "CAN Missing between BMS and Charger";
CM_ SG_ 958 ChargerHVOVHSC6 "The charger output voltage at charger HV side is overvoltage status";
CM_ SG_ 958 ChargerHVUVHSC6 "The charger output voltage at charger HV side is undervoltage status";
CM_ SG_ 958 ChargerInletTempOTPHSC6 "inlet air temperature is overtemperature status";
CM_ SG_ 958 ChargerInsideTemp1OTPHSC6 "charger internal temperature point 1 is overtemperature status";
CM_ SG_ 958 ChargerVinUVHSC6 "The input voltage is undervoltage status";
CM_ SG_ 958 ChrgrAltCrntLmtHSC6 "Charger Alternative Current Limit";
CM_ SG_ 958 ChrgrPriySideStwrOverCHSC6 "Charger Primary Side Software Over Current";
CM_ SG_ 659 BMSChgRelayStatusHSC6 "Charge contactor status";
CM_ SG_ 668 ChargerEnableHSC6 "charger enable";
CM_ SG_ 667 BMSVehicleEPOHSC6 "BMS EPO caused by vehicle";
CM_ SG_ 674 BMSClntTem_h6HSC6 "Battery Management System Coolant Temperature";
CM_ SG_ 674 BMSPumpSts_h6HSC6 "Battery Management System Pump Status";
CM_ SG_ 939 BMSOnbdChrgEnrgV_h6HSC6 "Battery Management System Onboard Charge Energy Validity";
CM_ SG_ 939 BMSOnbdChrgEnrg_h6HSC6 "Battery Management System Onboard Charge Energy";
CM_ SG_ 939 BMSPwrEfncyV_h6HSC6 "Battery Management System Power Efficiency Validity";
CM_ SG_ 939 BMSPwrEfncy_h6HSC6 "Battery Management System Power Efficiency";
CM_ SG_ 930 HVDCDCHVSideVolHSC6 "High Voltage Direct Current Direct Current High Voltage Side Voltage";
CM_ SG_ 930 HVDCDCHVSideVolVHSC6 "High Voltage Direct Current Direct Current High Voltage Side Voltage Validity";
CM_ SG_ 150 ISGInvtrCrntHSC6 "Integrated Starter Generator Inverter Current";
CM_ SG_ 150 ISGInvtrCrntVHSC6 "Integrated Starter Generator Inverter Current Validity";
CM_ SG_ 1053 TelmcsLclCalendarDayHSC6 "Telematics local Calendar Day";
CM_ SG_ 1053 TelmcsLclCalendarMonthHSC6 "Telematics local Calendar Month";
CM_ SG_ 1053 TelmcsLclCalendarYearHSC6 "Telematics local Calendar Year";
CM_ SG_ 1053 TelmcsLclHourOfDayHSC6 "Telematics local Hour of Day";
CM_ SG_ 1053 TelmcsLclMinuteOfHourHSC6 "Telematics local Minute Of Hour";
CM_ SG_ 1053 TelmcsLclSecsOfMinuteHSC6 "Telematics local Seconds of Minute";
BA_DEF_  "BaudRate" FLOAT 1000 1000000;
BA_DEF_ BO_  "GenMsgSendType" ENUM  "cyclic","Spontaneous","cyclicIfActive","spontaneousWithDelay","Immediate";
BA_DEF_ BO_  "GenMsgCycleTime" FLOAT 0 300000;
BA_DEF_ BO_  "GenMsgDelayTime" FLOAT 0 300000;
BA_DEF_ SG_  "GenSigStartValue" INT -9.22337203685478E+018 1.84467440737096E+019;
BA_DEF_ SG_  "GenSigPubLatency" INT 0 200;
BA_DEF_ SG_  "GenSigWriteInterval" INT 0 5000;
BA_DEF_DEF_  "BaudRate" 1000;
BA_DEF_DEF_  "GenMsgSendType" "";
BA_DEF_DEF_  "GenMsgCycleTime" 0;
BA_DEF_DEF_  "GenMsgDelayTime" 0;
BA_DEF_DEF_  "GenSigStartValue" 0;
BA_DEF_DEF_  "GenSigPubLatency" 0;
BA_DEF_DEF_  "GenSigWriteInterval" 0;
BA_ "BaudRate" 500000;
BA_ "GenMsgSendType" BO_ 952 0;
BA_ "GenMsgCycleTime" BO_ 952 100;
BA_ "GenMsgSendType" BO_ 954 0;
BA_ "GenMsgCycleTime" BO_ 954 100;
BA_ "GenMsgSendType" BO_ 956 0;
BA_ "GenMsgCycleTime" BO_ 956 100;
BA_ "GenMsgSendType" BO_ 958 0;
BA_ "GenMsgCycleTime" BO_ 958 100;
BA_ "GenMsgSendType" BO_ 659 0;
BA_ "GenMsgCycleTime" BO_ 659 50;
BA_ "GenMsgSendType" BO_ 661 0;
BA_ "GenMsgCycleTime" BO_ 661 20;
BA_ "GenMsgSendType" BO_ 663 0;
BA_ "GenMsgCycleTime" BO_ 663 50;
BA_ "GenMsgSendType" BO_ 369 0;
BA_ "GenMsgCycleTime" BO_ 369 20;
BA_ "GenMsgSendType" BO_ 668 0;
BA_ "GenMsgCycleTime" BO_ 668 100;
BA_ "GenMsgSendType" BO_ 665 0;
BA_ "GenMsgCycleTime" BO_ 665 50;
BA_ "GenMsgSendType" BO_ 667 0;
BA_ "GenMsgCycleTime" BO_ 667 50;
BA_ "GenMsgSendType" BO_ 1100 0;
BA_ "GenMsgCycleTime" BO_ 1100 100;
BA_ "GenMsgSendType" BO_ 370 0;
BA_ "GenMsgCycleTime" BO_ 370 20;
BA_ "GenMsgSendType" BO_ 371 0;
BA_ "GenMsgCycleTime" BO_ 371 20;
BA_ "GenMsgSendType" BO_ 674 0;
BA_ "GenMsgCycleTime" BO_ 674 100;
BA_ "GenMsgSendType" BO_ 939 0;
BA_ "GenMsgCycleTime" BO_ 939 100;
BA_ "GenMsgSendType" BO_ 940 0;
BA_ "GenMsgCycleTime" BO_ 940 100;
BA_ "GenMsgSendType" BO_ 913 0;
BA_ "GenMsgCycleTime" BO_ 913 100;
BA_ "GenMsgSendType" BO_ 915 0;
BA_ "GenMsgCycleTime" BO_ 915 100;
BA_ "GenMsgSendType" BO_ 936 0;
BA_ "GenMsgCycleTime" BO_ 936 100;
BA_ "GenMsgSendType" BO_ 1091 1;
BA_ "GenMsgSendType" BO_ 916 0;
BA_ "GenMsgCycleTime" BO_ 916 100;
BA_ "GenMsgSendType" BO_ 138 0;
BA_ "GenMsgCycleTime" BO_ 138 10;
BA_ "GenMsgSendType" BO_ 854 0;
BA_ "GenMsgCycleTime" BO_ 854 100;
BA_ "GenMsgSendType" BO_ 856 0;
BA_ "GenMsgCycleTime" BO_ 856 100;
BA_ "GenMsgSendType" BO_ 1055 4;
BA_ "GenMsgSendType" BO_ 153 0;
BA_ "GenMsgCycleTime" BO_ 153 10;
BA_ "GenMsgSendType" BO_ 331 0;
BA_ "GenMsgCycleTime" BO_ 331 10;
BA_ "GenMsgSendType" BO_ 930 0;
BA_ "GenMsgCycleTime" BO_ 930 10;
BA_ "GenMsgSendType" BO_ 150 0;
BA_ "GenMsgCycleTime" BO_ 150 10;
BA_ "GenMsgSendType" BO_ 1053 0;
BA_ "GenMsgCycleTime" BO_ 1053 200;
BA_ "GenSigPubLatency" SG_ 952 ChargerACCurrentHSC6 10;
BA_ "GenSigWriteInterval" SG_ 952 ChargerACCurrentHSC6 100;
BA_ "GenSigPubLatency" SG_ 952 ChargerACVoltHSC6 10;
BA_ "GenSigWriteInterval" SG_ 952 ChargerACVoltHSC6 100;
BA_ "GenSigPubLatency" SG_ 952 ChargerFanStatusHSC6 10;
BA_ "GenSigWriteInterval" SG_ 952 ChargerFanStatusHSC6 100;
BA_ "GenSigPubLatency" SG_ 952 ChargerHVCurrentHSC6 10;
BA_ "GenSigWriteInterval" SG_ 952 ChargerHVCurrentHSC6 100;
BA_ "GenSigPubLatency" SG_ 952 ChargerHVRelayStatusHSC6 10;
BA_ "GenSigWriteInterval" SG_ 952 ChargerHVRelayStatusHSC6 100;
BA_ "GenSigPubLatency" SG_ 952 ChargerHVVoltHSC6 10;
BA_ "GenSigWriteInterval" SG_ 952 ChargerHVVoltHSC6 100;
BA_ "GenSigPubLatency" SG_ 952 ChargerStatusHSC6 10;
BA_ "GenSigWriteInterval" SG_ 952 ChargerStatusHSC6 100;
BA_ "GenSigPubLatency" SG_ 952 ChargerWakeUpHSC6 10;
BA_ "GenSigWriteInterval" SG_ 952 ChargerWakeUpHSC6 100;
BA_ "GenSigPubLatency" SG_ 954 BMSCellMaxTemIndxHSC6 20;
BA_ "GenSigStartValue" SG_ 954 BMSCellMaxTemIndxHSC6 255;
BA_ "GenSigPubLatency" SG_ 954 BMSCellMaxVolIndxHSC6 20;
BA_ "GenSigStartValue" SG_ 954 BMSCellMaxVolIndxHSC6 255;
BA_ "GenSigPubLatency" SG_ 954 BMSCellMinTemIndxHSC6 20;
BA_ "GenSigStartValue" SG_ 954 BMSCellMinTemIndxHSC6 255;
BA_ "GenSigPubLatency" SG_ 954 BMSCellMinVolIndxHSC6 20;
BA_ "GenSigStartValue" SG_ 954 BMSCellMinVolIndxHSC6 255;
BA_ "GenSigPubLatency" SG_ 956 ChargerLVCurrentHSC6 10;
BA_ "GenSigWriteInterval" SG_ 956 ChargerLVCurrentHSC6 100;
BA_ "GenSigPubLatency" SG_ 956 ChargerLVVoltHSC6 10;
BA_ "GenSigWriteInterval" SG_ 956 ChargerLVVoltHSC6 100;
BA_ "GenSigPubLatency" SG_ 958 BMSCellTemHSC6 20;
BA_ "GenSigStartValue" SG_ 958 BMSCellTemHSC6 48.191;
BA_ "GenSigPubLatency" SG_ 958 BMSCellTemIndxHSC6 20;
BA_ "GenSigStartValue" SG_ 958 BMSCellTemIndxHSC6 255;
BA_ "GenSigPubLatency" SG_ 958 BMSCellTemVHSC6 20;
BA_ "GenSigStartValue" SG_ 958 BMSCellTemVHSC6 1;
BA_ "GenSigPubLatency" SG_ 958 BMSCellVolHSC6 20;
BA_ "GenSigStartValue" SG_ 958 BMSCellVolHSC6 4095;
BA_ "GenSigPubLatency" SG_ 958 BMSCellVolIndxHSC6 20;
BA_ "GenSigStartValue" SG_ 958 BMSCellVolIndxHSC6 255;
BA_ "GenSigPubLatency" SG_ 958 BMSCellVolVHSC6 20;
BA_ "GenSigStartValue" SG_ 958 BMSCellVolVHSC6 1;
BA_ "GenSigPubLatency" SG_ 659 BMSBalancingDoneHSC6 10;
BA_ "GenSigWriteInterval" SG_ 659 BMSBalancingDoneHSC6 100;
BA_ "GenSigPubLatency" SG_ 659 BMSBalancingStatusHSC6 10;
BA_ "GenSigWriteInterval" SG_ 659 BMSBalancingStatusHSC6 100;
BA_ "GenSigPubLatency" SG_ 659 BMSCellBalancingCountHSC6 10;
BA_ "GenSigWriteInterval" SG_ 659 BMSCellBalancingCountHSC6 100;
BA_ "GenSigStartValue" SG_ 659 BMSCellBalancingCountHSC6 255;
BA_ "GenSigPubLatency" SG_ 659 BMSCellOverVoltHSC6 10;
BA_ "GenSigWriteInterval" SG_ 659 BMSCellOverVoltHSC6 100;
BA_ "GenSigPubLatency" SG_ 659 BMSCellUnderVoltHSC6 10;
BA_ "GenSigWriteInterval" SG_ 659 BMSCellUnderVoltHSC6 100;
BA_ "GenSigPubLatency" SG_ 659 BMSContactorPowerCmdHSC6 10;
BA_ "GenSigWriteInterval" SG_ 659 BMSContactorPowerCmdHSC6 100;
BA_ "GenSigPubLatency" SG_ 659 BMSContactorPowerMonHSC6 10;
BA_ "GenSigWriteInterval" SG_ 659 BMSContactorPowerMonHSC6 100;
BA_ "GenSigPubLatency" SG_ 659 BMSCrashCircuitStatusHSC6 10;
BA_ "GenSigWriteInterval" SG_ 659 BMSCrashCircuitStatusHSC6 100;
BA_ "GenSigPubLatency" SG_ 659 BMSEEpromWipHSC6 10;
BA_ "GenSigWriteInterval" SG_ 659 BMSEEpromWipHSC6 100;
BA_ "GenSigPubLatency" SG_ 659 BMSLVBatInputHSC6 10;
BA_ "GenSigWriteInterval" SG_ 659 BMSLVBatInputHSC6 100;
BA_ "GenSigStartValue" SG_ 659 BMSLVBatInputHSC6 255;
BA_ "GenSigPubLatency" SG_ 659 BMSModuleEnableHSC6 10;
BA_ "GenSigWriteInterval" SG_ 659 BMSModuleEnableHSC6 100;
BA_ "GenSigPubLatency" SG_ 659 BMSNegRelayStatusHSC6 10;
BA_ "GenSigWriteInterval" SG_ 659 BMSNegRelayStatusHSC6 100;
BA_ "GenSigPubLatency" SG_ 659 BMSOffbdChargerWakeupHSC6 10;
BA_ "GenSigWriteInterval" SG_ 659 BMSOffbdChargerWakeupHSC6 100;
BA_ "GenSigPubLatency" SG_ 659 BMSOnbdChargerWakeupHSC6 10;
BA_ "GenSigWriteInterval" SG_ 659 BMSOnbdChargerWakeupHSC6 100;
BA_ "GenSigPubLatency" SG_ 659 BMSPosRelayStatusHSC6 10;
BA_ "GenSigWriteInterval" SG_ 659 BMSPosRelayStatusHSC6 100;
BA_ "GenSigPubLatency" SG_ 659 BMSPreRelayStatusHSC6 10;
BA_ "GenSigWriteInterval" SG_ 659 BMSPreRelayStatusHSC6 100;
BA_ "GenSigPubLatency" SG_ 659 BMSPTIsolationLevelHSC6 10;
BA_ "GenSigWriteInterval" SG_ 659 BMSPTIsolationLevelHSC6 100;
BA_ "GenSigPubLatency" SG_ 659 BMSReadyHSC6 10;
BA_ "GenSigWriteInterval" SG_ 659 BMSReadyHSC6 100;
BA_ "GenSigPubLatency" SG_ 659 BMSRelayStepHSC6 10;
BA_ "GenSigWriteInterval" SG_ 659 BMSRelayStepHSC6 100;
BA_ "GenSigPubLatency" SG_ 659 BMSVehicleWakeupHSC6 10;
BA_ "GenSigWriteInterval" SG_ 659 BMSVehicleWakeupHSC6 100;
BA_ "GenSigPubLatency" SG_ 661 BMSChecksum01HSC6 10;
BA_ "GenSigWriteInterval" SG_ 661 BMSChecksum01HSC6 100;
BA_ "GenSigPubLatency" SG_ 661 BMSCounter01HSC6 10;
BA_ "GenSigWriteInterval" SG_ 661 BMSCounter01HSC6 100;
BA_ "GenSigPubLatency" SG_ 661 BMSPackCrntV_h6HSC6 20;
BA_ "GenSigStartValue" SG_ 661 BMSPackCrntV_h6HSC6 1;
BA_ "GenSigPubLatency" SG_ 661 BMSPackCrnt_h6HSC6 20;
BA_ "GenSigStartValue" SG_ 661 BMSPackCrnt_h6HSC6 65535;
BA_ "GenSigPubLatency" SG_ 661 BMSPackSOCV_h6HSC6 10;
BA_ "GenSigWriteInterval" SG_ 661 BMSPackSOCV_h6HSC6 100;
BA_ "GenSigStartValue" SG_ 661 BMSPackSOCV_h6HSC6 1;
BA_ "GenSigPubLatency" SG_ 661 BMSPackSOC_h6HSC6 10;
BA_ "GenSigWriteInterval" SG_ 661 BMSPackSOC_h6HSC6 100;
BA_ "GenSigStartValue" SG_ 661 BMSPackSOC_h6HSC6 1023;
BA_ "GenSigPubLatency" SG_ 661 BMSPackVolV_h6HSC6 20;
BA_ "GenSigStartValue" SG_ 661 BMSPackVolV_h6HSC6 1;
BA_ "GenSigPubLatency" SG_ 661 BMSPackVol_h6HSC6 20;
BA_ "GenSigStartValue" SG_ 661 BMSPackVol_h6HSC6 4095;
BA_ "GenSigPubLatency" SG_ 663 BMSBscStaHSC6 10;
BA_ "GenSigWriteInterval" SG_ 663 BMSBscStaHSC6 100;
BA_ "GenSigPubLatency" SG_ 663 BMSCdstCtrHSC6 10;
BA_ "GenSigWriteInterval" SG_ 663 BMSCdstCtrHSC6 100;
BA_ "GenSigPubLatency" SG_ 663 BMSChecksum02HSC6 10;
BA_ "GenSigWriteInterval" SG_ 663 BMSChecksum02HSC6 100;
BA_ "GenSigPubLatency" SG_ 663 BMSCounter02HSC6 10;
BA_ "GenSigWriteInterval" SG_ 663 BMSCounter02HSC6 100;
BA_ "GenSigPubLatency" SG_ 663 BMSFltLvlHSC6 10;
BA_ "GenSigWriteInterval" SG_ 663 BMSFltLvlHSC6 100;
BA_ "GenSigPubLatency" SG_ 663 BMSHVILClsdHSC6 10;
BA_ "GenSigWriteInterval" SG_ 663 BMSHVILClsdHSC6 100;
BA_ "GenSigStartValue" SG_ 663 BMSHVILClsdHSC6 1;
BA_ "GenSigPubLatency" SG_ 663 BMSMainRelaySts_h6HSC6 10;
BA_ "GenSigWriteInterval" SG_ 663 BMSMainRelaySts_h6HSC6 100;
BA_ "GenSigPubLatency" SG_ 663 BMSOfbdChrgRelayStsHSC6 10;
BA_ "GenSigWriteInterval" SG_ 663 BMSOfbdChrgRelayStsHSC6 100;
BA_ "GenSigPubLatency" SG_ 663 BMSOnbdChrgRelayStsHSC6 10;
BA_ "GenSigWriteInterval" SG_ 663 BMSOnbdChrgRelayStsHSC6 100;
BA_ "GenSigPubLatency" SG_ 663 BMSPtIsltnRstcHSC6 10;
BA_ "GenSigWriteInterval" SG_ 663 BMSPtIsltnRstcHSC6 100;
BA_ "GenSigStartValue" SG_ 663 BMSPtIsltnRstcHSC6 16383;
BA_ "GenSigPubLatency" SG_ 663 BMSPtIsltnRstcVHSC6 10;
BA_ "GenSigWriteInterval" SG_ 663 BMSPtIsltnRstcVHSC6 100;
BA_ "GenSigStartValue" SG_ 663 BMSPtIsltnRstcVHSC6 1;
BA_ "GenSigPubLatency" SG_ 663 BMSVehEmgcPwrOffHSC6 10;
BA_ "GenSigWriteInterval" SG_ 663 BMSVehEmgcPwrOffHSC6 100;
BA_ "GenSigStartValue" SG_ 663 BMSVehEmgcPwrOffHSC6 14;
BA_ "GenSigPubLatency" SG_ 663 OffbdChrgrSysKeepAwkHSC6 20;
BA_ "GenSigPubLatency" SG_ 663 OnbdChrgrSktEleccLckEHSC6 10;
BA_ "GenSigPubLatency" SG_ 663 OnbdChrgrSysKeepAwkHSC6 10;
BA_ "GenSigPubLatency" SG_ 369 BMSChecksum03HSC6 10;
BA_ "GenSigWriteInterval" SG_ 369 BMSChecksum03HSC6 100;
BA_ "GenSigPubLatency" SG_ 369 BMSChrgCrntLmtHSC6 10;
BA_ "GenSigWriteInterval" SG_ 369 BMSChrgCrntLmtHSC6 100;
BA_ "GenSigPubLatency" SG_ 369 BMSChrgCrntLmtVHSC6 10;
BA_ "GenSigWriteInterval" SG_ 369 BMSChrgCrntLmtVHSC6 100;
BA_ "GenSigStartValue" SG_ 369 BMSChrgCrntLmtVHSC6 1;
BA_ "GenSigPubLatency" SG_ 369 BMSCounter03HSC6 10;
BA_ "GenSigWriteInterval" SG_ 369 BMSCounter03HSC6 100;
BA_ "GenSigPubLatency" SG_ 369 BMSDschrgCrntLmtHSC6 10;
BA_ "GenSigWriteInterval" SG_ 369 BMSDschrgCrntLmtHSC6 100;
BA_ "GenSigStartValue" SG_ 369 BMSDschrgCrntLmtHSC6 1023;
BA_ "GenSigPubLatency" SG_ 369 BMSDschrgCrntLmtVHSC6 10;
BA_ "GenSigWriteInterval" SG_ 369 BMSDschrgCrntLmtVHSC6 100;
BA_ "GenSigStartValue" SG_ 369 BMSDschrgCrntLmtVHSC6 1;
BA_ "GenSigPubLatency" SG_ 369 BMSMaxVolLmtHSC6 10;
BA_ "GenSigWriteInterval" SG_ 369 BMSMaxVolLmtHSC6 100;
BA_ "GenSigStartValue" SG_ 369 BMSMaxVolLmtHSC6 1023;
BA_ "GenSigPubLatency" SG_ 369 BMSMaxVolLmtVHSC6 10;
BA_ "GenSigWriteInterval" SG_ 369 BMSMaxVolLmtVHSC6 100;
BA_ "GenSigStartValue" SG_ 369 BMSMaxVolLmtVHSC6 1;
BA_ "GenSigPubLatency" SG_ 369 BMSMinVolLmtHSC6 10;
BA_ "GenSigWriteInterval" SG_ 369 BMSMinVolLmtHSC6 100;
BA_ "GenSigStartValue" SG_ 369 BMSMinVolLmtHSC6 1023;
BA_ "GenSigPubLatency" SG_ 369 BMSMinVolLmtVHSC6 10;
BA_ "GenSigWriteInterval" SG_ 369 BMSMinVolLmtVHSC6 100;
BA_ "GenSigStartValue" SG_ 369 BMSMinVolLmtVHSC6 1;
BA_ "GenSigPubLatency" SG_ 668 ChargeCurrentHSC6 10;
BA_ "GenSigWriteInterval" SG_ 668 ChargeCurrentHSC6 100;
BA_ "GenSigPubLatency" SG_ 668 ChargePowerHSC6 10;
BA_ "GenSigWriteInterval" SG_ 668 ChargePowerHSC6 100;
BA_ "GenSigPubLatency" SG_ 668 ChargerCapacityHSC6 10;
BA_ "GenSigWriteInterval" SG_ 668 ChargerCapacityHSC6 100;
BA_ "GenSigPubLatency" SG_ 668 ChargerInletTempHSC6 20;
BA_ "GenSigPubLatency" SG_ 668 ChargerModeHSC6 10;
BA_ "GenSigWriteInterval" SG_ 668 ChargerModeHSC6 100;
BA_ "GenSigPubLatency" SG_ 668 ChargerVoltageHSC6 10;
BA_ "GenSigStartValue" SG_ 668 ChargerVoltageHSC6 511;
BA_ "GenSigPubLatency" SG_ 665 BMSFlameGasStatusHSC6 10;
BA_ "GenSigWriteInterval" SG_ 665 BMSFlameGasStatusHSC6 100;
BA_ "GenSigStartValue" SG_ 665 BMSFlameGasStatusHSC6 255;
BA_ "GenSigPubLatency" SG_ 665 BMSFltCtHSC6 10;
BA_ "GenSigWriteInterval" SG_ 665 BMSFltCtHSC6 100;
BA_ "GenSigStartValue" SG_ 665 BMSFltCtHSC6 255;
BA_ "GenSigPubLatency" SG_ 665 BMSNegativeBusVoltHSC6 10;
BA_ "GenSigWriteInterval" SG_ 665 BMSNegativeBusVoltHSC6 100;
BA_ "GenSigStartValue" SG_ 665 BMSNegativeBusVoltHSC6 4095;
BA_ "GenSigPubLatency" SG_ 665 BMSPackCurrent2HSC6 10;
BA_ "GenSigWriteInterval" SG_ 665 BMSPackCurrent2HSC6 100;
BA_ "GenSigStartValue" SG_ 665 BMSPackCurrent2HSC6 65535;
BA_ "GenSigPubLatency" SG_ 665 BMSPackSOCActualHSC6 10;
BA_ "GenSigWriteInterval" SG_ 665 BMSPackSOCActualHSC6 100;
BA_ "GenSigStartValue" SG_ 665 BMSPackSOCActualHSC6 254;
BA_ "GenSigPubLatency" SG_ 665 BMSPositiveBusVoltHSC6 10;
BA_ "GenSigWriteInterval" SG_ 665 BMSPositiveBusVoltHSC6 100;
BA_ "GenSigStartValue" SG_ 665 BMSPositiveBusVoltHSC6 4095;
BA_ "GenSigPubLatency" SG_ 667 BMSBusbarTempMaxHSC6 10;
BA_ "GenSigWriteInterval" SG_ 667 BMSBusbarTempMaxHSC6 100;
BA_ "GenSigPubLatency" SG_ 667 BMSChgIngDriverStatHSC6 10;
BA_ "GenSigWriteInterval" SG_ 667 BMSChgIngDriverStatHSC6 100;
BA_ "GenSigPubLatency" SG_ 667 BMSChrgrPlugCnctnIO_h6HSC6 10;
BA_ "GenSigStartValue" SG_ 667 BMSChrgrPlugCnctnIO_h6HSC6 1;
BA_ "GenSigPubLatency" SG_ 667 BMSChrgStsIO_h6HSC6 10;
BA_ "GenSigStartValue" SG_ 667 BMSChrgStsIO_h6HSC6 1;
BA_ "GenSigPubLatency" SG_ 667 BMSConIndDriverStatHSC6 20;
BA_ "GenSigStartValue" SG_ 667 BMSConIndDriverStatHSC6 1;
BA_ "GenSigPubLatency" SG_ 667 BMSLiquidSensorStHSC6 10;
BA_ "GenSigWriteInterval" SG_ 667 BMSLiquidSensorStHSC6 100;
BA_ "GenSigPubLatency" SG_ 667 BMSPackSOHHSC6 10;
BA_ "GenSigWriteInterval" SG_ 667 BMSPackSOHHSC6 100;
BA_ "GenSigStartValue" SG_ 667 BMSPackSOHHSC6 1022;
BA_ "GenSigPubLatency" SG_ 667 BMSStaOfHealthCapctHSC6 10;
BA_ "GenSigWriteInterval" SG_ 667 BMSStaOfHealthCapctHSC6 100;
BA_ "GenSigStartValue" SG_ 667 BMSStaOfHealthCapctHSC6 255;
BA_ "GenSigPubLatency" SG_ 667 BMSStaOfHealthResiHSC6 10;
BA_ "GenSigWriteInterval" SG_ 667 BMSStaOfHealthResiHSC6 100;
BA_ "GenSigStartValue" SG_ 667 BMSStaOfHealthResiHSC6 255;
BA_ "GenSigPubLatency" SG_ 1100 keep_network_BMSHSC6 10;
BA_ "GenSigWriteInterval" SG_ 1100 keep_network_BMSHSC6 10;
BA_ "GenSigPubLatency" SG_ 370 BMSChrgPeakPwrHSC6 10;
BA_ "GenSigWriteInterval" SG_ 370 BMSChrgPeakPwrHSC6 100;
BA_ "GenSigStartValue" SG_ 370 BMSChrgPeakPwrHSC6 2047;
BA_ "GenSigPubLatency" SG_ 370 BMSChrgPeakPwrVHSC6 10;
BA_ "GenSigWriteInterval" SG_ 370 BMSChrgPeakPwrVHSC6 100;
BA_ "GenSigStartValue" SG_ 370 BMSChrgPeakPwrVHSC6 1;
BA_ "GenSigPubLatency" SG_ 370 BMSChrgPwrLmtHSC6 10;
BA_ "GenSigWriteInterval" SG_ 370 BMSChrgPwrLmtHSC6 100;
BA_ "GenSigStartValue" SG_ 370 BMSChrgPwrLmtHSC6 2047;
BA_ "GenSigPubLatency" SG_ 370 BMSChrgPwrLmtVHSC6 10;
BA_ "GenSigWriteInterval" SG_ 370 BMSChrgPwrLmtVHSC6 100;
BA_ "GenSigStartValue" SG_ 370 BMSChrgPwrLmtVHSC6 1;
BA_ "GenSigPubLatency" SG_ 370 BMSDschrgPeakPwrHSC6 10;
BA_ "GenSigWriteInterval" SG_ 370 BMSDschrgPeakPwrHSC6 100;
BA_ "GenSigStartValue" SG_ 370 BMSDschrgPeakPwrHSC6 2047;
BA_ "GenSigPubLatency" SG_ 370 BMSDschrgPeakPwrVHSC6 10;
BA_ "GenSigWriteInterval" SG_ 370 BMSDschrgPeakPwrVHSC6 100;
BA_ "GenSigStartValue" SG_ 370 BMSDschrgPeakPwrVHSC6 1;
BA_ "GenSigPubLatency" SG_ 370 BMSDschrgPwrLmtHSC6 10;
BA_ "GenSigWriteInterval" SG_ 370 BMSDschrgPwrLmtHSC6 100;
BA_ "GenSigStartValue" SG_ 370 BMSDschrgPwrLmtHSC6 2047;
BA_ "GenSigPubLatency" SG_ 370 BMSDschrgPwrLmtVHSC6 10;
BA_ "GenSigWriteInterval" SG_ 370 BMSDschrgPwrLmtVHSC6 100;
BA_ "GenSigStartValue" SG_ 370 BMSDschrgPwrLmtVHSC6 1;
BA_ "GenSigPubLatency" SG_ 371 BMSCellMaxVolHSC6 10;
BA_ "GenSigWriteInterval" SG_ 371 BMSCellMaxVolHSC6 100;
BA_ "GenSigStartValue" SG_ 371 BMSCellMaxVolHSC6 8191;
BA_ "GenSigPubLatency" SG_ 371 BMSCellMaxVolVHSC6 10;
BA_ "GenSigWriteInterval" SG_ 371 BMSCellMaxVolVHSC6 100;
BA_ "GenSigStartValue" SG_ 371 BMSCellMaxVolVHSC6 1;
BA_ "GenSigPubLatency" SG_ 371 BMSCellMinVolHSC6 10;
BA_ "GenSigWriteInterval" SG_ 371 BMSCellMinVolHSC6 100;
BA_ "GenSigStartValue" SG_ 371 BMSCellMinVolHSC6 8191;
BA_ "GenSigPubLatency" SG_ 371 BMSCellMinVolVHSC6 10;
BA_ "GenSigWriteInterval" SG_ 371 BMSCellMinVolVHSC6 100;
BA_ "GenSigStartValue" SG_ 371 BMSCellMinVolVHSC6 1;
BA_ "GenSigPubLatency" SG_ 371 BMSChrgBufHSC6 10;
BA_ "GenSigWriteInterval" SG_ 371 BMSChrgBufHSC6 100;
BA_ "GenSigStartValue" SG_ 371 BMSChrgBufHSC6 255;
BA_ "GenSigPubLatency" SG_ 371 BMSChrgBufVHSC6 10;
BA_ "GenSigWriteInterval" SG_ 371 BMSChrgBufVHSC6 100;
BA_ "GenSigStartValue" SG_ 371 BMSChrgBufVHSC6 1;
BA_ "GenSigPubLatency" SG_ 371 BMSDschrgBufHSC6 10;
BA_ "GenSigWriteInterval" SG_ 371 BMSDschrgBufHSC6 100;
BA_ "GenSigStartValue" SG_ 371 BMSDschrgBufHSC6 255;
BA_ "GenSigPubLatency" SG_ 371 BMSDschrgBufVHSC6 10;
BA_ "GenSigWriteInterval" SG_ 371 BMSDschrgBufVHSC6 100;
BA_ "GenSigStartValue" SG_ 371 BMSDschrgBufVHSC6 1;
BA_ "GenSigPubLatency" SG_ 674 BMSCellMaxTemV_h6HSC6 10;
BA_ "GenSigWriteInterval" SG_ 674 BMSCellMaxTemV_h6HSC6 100;
BA_ "GenSigStartValue" SG_ 674 BMSCellMaxTemV_h6HSC6 1;
BA_ "GenSigPubLatency" SG_ 674 BMSCellMaxTem_h6HSC6 10;
BA_ "GenSigWriteInterval" SG_ 674 BMSCellMaxTem_h6HSC6 100;
BA_ "GenSigStartValue" SG_ 674 BMSCellMaxTem_h6HSC6 255;
BA_ "GenSigPubLatency" SG_ 674 BMSCellMinTemV_h6HSC6 10;
BA_ "GenSigWriteInterval" SG_ 674 BMSCellMinTemV_h6HSC6 100;
BA_ "GenSigStartValue" SG_ 674 BMSCellMinTemV_h6HSC6 1;
BA_ "GenSigPubLatency" SG_ 674 BMSCellMinTem_h6HSC6 10;
BA_ "GenSigWriteInterval" SG_ 674 BMSCellMinTem_h6HSC6 100;
BA_ "GenSigStartValue" SG_ 674 BMSCellMinTem_h6HSC6 255;
BA_ "GenSigPubLatency" SG_ 674 BMSChrgReqHSC6 10;
BA_ "GenSigWriteInterval" SG_ 674 BMSChrgReqHSC6 100;
BA_ "GenSigPubLatency" SG_ 674 BMSOdoFctHSC6 10;
BA_ "GenSigWriteInterval" SG_ 674 BMSOdoFctHSC6 100;
BA_ "GenSigPubLatency" SG_ 674 BMSOfbdChrgrPlugOnHSC6 10;
BA_ "GenSigWriteInterval" SG_ 674 BMSOfbdChrgrPlugOnHSC6 100;
BA_ "GenSigPubLatency" SG_ 674 BMSOnbdChrgrPlugOn_h6HSC6 10;
BA_ "GenSigPubLatency" SG_ 674 VehElecRng_h6HSC6 10;
BA_ "GenSigStartValue" SG_ 674 VehElecRng_h6HSC6 2046;
BA_ "GenSigPubLatency" SG_ 939 BMSAvlblEnrg_h6HSC6 10;
BA_ "GenSigStartValue" SG_ 939 BMSAvlblEnrg_h6HSC6 255;
BA_ "GenSigPubLatency" SG_ 939 HVBatElecEnrgAvgRate_h6HSC6 10;
BA_ "GenSigStartValue" SG_ 939 HVBatElecEnrgAvgRate_h6HSC6 1023;
BA_ "GenSigPubLatency" SG_ 940 BMSPackSOCDsp_h6HSC6 20;
BA_ "GenSigStartValue" SG_ 940 BMSPackSOCDsp_h6HSC6 1022;
BA_ "GenSigPubLatency" SG_ 913 BMSChrgSts_h6HSC6 20;
BA_ "GenSigPubLatency" SG_ 913 BMSReserDurtnTimeDspCmd_h6HSC6 20;
BA_ "GenSigStartValue" SG_ 913 BMSReserDurtnTimeDspCmd_h6HSC6 62;
BA_ "GenSigPubLatency" SG_ 913 BMSReserPushItemHSC6 20;
BA_ "GenSigPubLatency" SG_ 913 BMSReserStDurtnTimeDspCmdHSC6 20;
BA_ "GenSigStartValue" SG_ 913 BMSReserStDurtnTimeDspCmdHSC6 30;
BA_ "GenSigPubLatency" SG_ 913 BMSReserStHourDspCmdHSC6 20;
BA_ "GenSigStartValue" SG_ 913 BMSReserStHourDspCmdHSC6 30;
BA_ "GenSigPubLatency" SG_ 913 BMSReserStMinuteDspCmdHSC6 20;
BA_ "GenSigStartValue" SG_ 913 BMSReserStMinuteDspCmdHSC6 62;
BA_ "GenSigPubLatency" SG_ 915 BMSReserChrgCtrlDspCmdHSC6 20;
BA_ "GenSigPubLatency" SG_ 915 BMSReserChrgEnrgDspCmd_h6HSC6 20;
BA_ "GenSigStartValue" SG_ 915 BMSReserChrgEnrgDspCmd_h6HSC6 62;
BA_ "GenSigPubLatency" SG_ 915 BMSReserChrgFltReasonHSC6 20;
BA_ "GenSigPubLatency" SG_ 915 BMSReserChrgFrqcDspCmdHSC6 20;
BA_ "GenSigPubLatency" SG_ 915 BMSReserChrgMdDspCmd_h6HSC6 20;
BA_ "GenSigPubLatency" SG_ 915 BMSReserChrgRespVHSC6 20;
BA_ "GenSigPubLatency" SG_ 915 BMSReserChrgRngDspCmd_h6HSC6 20;
BA_ "GenSigStartValue" SG_ 915 BMSReserChrgRngDspCmd_h6HSC6 1022;
BA_ "GenSigPubLatency" SG_ 915 BMSReserFltReasonHSC6 20;
BA_ "GenSigPubLatency" SG_ 915 BMSReserMaxCrntDspCmd_h6HSC6 20;
BA_ "GenSigStartValue" SG_ 915 BMSReserMaxCrntDspCmd_h6HSC6 62;
BA_ "GenSigPubLatency" SG_ 915 BMSReserStaDspCmdHSC6 20;
BA_ "GenSigPubLatency" SG_ 915 BMSReserTrgtSOCDspCmd_h6HSC6 20;
BA_ "GenSigStartValue" SG_ 915 BMSReserTrgtSOCDspCmd_h6HSC6 1022;
BA_ "GenSigPubLatency" SG_ 936 ChrgngRmnngTimeV_h6HSC6 20;
BA_ "GenSigStartValue" SG_ 936 ChrgngRmnngTimeV_h6HSC6 1;
BA_ "GenSigPubLatency" SG_ 936 ChrgngRmnngTime_h6HSC6 20;
BA_ "GenSigStartValue" SG_ 936 ChrgngRmnngTime_h6HSC6 1023;
BA_ "GenSigPubLatency" SG_ 1091 wake_network_BMSHSC6 10;
BA_ "GenSigWriteInterval" SG_ 1091 wake_network_BMSHSC6 10;
BA_ "GenSigPubLatency" SG_ 916 EPTChrgCoolngSysStsHSC6 10;
BA_ "GenSigWriteInterval" SG_ 916 EPTChrgCoolngSysStsHSC6 100;
BA_ "GenSigPubLatency" SG_ 916 OfbdChrgrNgtvSktTemHSC6 10;
BA_ "GenSigWriteInterval" SG_ 916 OfbdChrgrNgtvSktTemHSC6 100;
BA_ "GenSigStartValue" SG_ 916 OfbdChrgrNgtvSktTemHSC6 254;
BA_ "GenSigPubLatency" SG_ 916 OfbdChrgrNgtvSktTemVHSC6 10;
BA_ "GenSigWriteInterval" SG_ 916 OfbdChrgrNgtvSktTemVHSC6 100;
BA_ "GenSigStartValue" SG_ 916 OfbdChrgrNgtvSktTemVHSC6 1;
BA_ "GenSigPubLatency" SG_ 916 OfbdChrgrPstvSktTemHSC6 10;
BA_ "GenSigWriteInterval" SG_ 916 OfbdChrgrPstvSktTemHSC6 100;
BA_ "GenSigStartValue" SG_ 916 OfbdChrgrPstvSktTemHSC6 254;
BA_ "GenSigPubLatency" SG_ 916 OfbdChrgrPstvSktTemVHSC6 10;
BA_ "GenSigWriteInterval" SG_ 916 OfbdChrgrPstvSktTemVHSC6 100;
BA_ "GenSigStartValue" SG_ 916 OfbdChrgrPstvSktTemVHSC6 1;
BA_ "GenSigPubLatency" SG_ 916 OnbdChrgrSktEleccLckSHSC6 10;
BA_ "GenSigPubLatency" SG_ 138 EPTHVBatPwrRlseReqHSC6 10;
BA_ "GenSigWriteInterval" SG_ 138 EPTHVBatPwrRlseReqHSC6 100;
BA_ "GenSigPubLatency" SG_ 138 EPTHVEmgcPwrOffReqHSC6 10;
BA_ "GenSigWriteInterval" SG_ 138 EPTHVEmgcPwrOffReqHSC6 100;
BA_ "GenSigPubLatency" SG_ 138 EPTMainRelayDrvReqHSC6 10;
BA_ "GenSigWriteInterval" SG_ 138 EPTMainRelayDrvReqHSC6 100;
BA_ "GenSigPubLatency" SG_ 138 HCUChecksum05HSC6 10;
BA_ "GenSigWriteInterval" SG_ 138 HCUChecksum05HSC6 100;
BA_ "GenSigPubLatency" SG_ 138 HCUCounter05HSC6 10;
BA_ "GenSigWriteInterval" SG_ 138 HCUCounter05HSC6 100;
BA_ "GenSigPubLatency" SG_ 854 TBOXReserDurtnTimeHSC6 20;
BA_ "GenSigStartValue" SG_ 854 TBOXReserDurtnTimeHSC6 62;
BA_ "GenSigPubLatency" SG_ 854 TBOXReserStDayHSC6 20;
BA_ "GenSigStartValue" SG_ 854 TBOXReserStDayHSC6 30;
BA_ "GenSigPubLatency" SG_ 854 TBOXReserStDurtnTimeHSC6 20;
BA_ "GenSigStartValue" SG_ 854 TBOXReserStDurtnTimeHSC6 30;
BA_ "GenSigPubLatency" SG_ 854 TBOXReserStHourHSC6 20;
BA_ "GenSigStartValue" SG_ 854 TBOXReserStHourHSC6 30;
BA_ "GenSigPubLatency" SG_ 854 TBOXReserStMinuteHSC6 20;
BA_ "GenSigStartValue" SG_ 854 TBOXReserStMinuteHSC6 62;
BA_ "GenSigPubLatency" SG_ 854 TBOXReserStMonthHSC6 20;
BA_ "GenSigPubLatency" SG_ 854 TBOXReserStTimeChksmHSC6 20;
BA_ "GenSigStartValue" SG_ 854 TBOXReserStTimeChksmHSC6 254;
BA_ "GenSigPubLatency" SG_ 854 TBOXReserStYearHSC6 20;
BA_ "GenSigStartValue" SG_ 854 TBOXReserStYearHSC6 254;
BA_ "GenSigPubLatency" SG_ 856 TBOXReserChrgCtrlReqHSC6 20;
BA_ "GenSigPubLatency" SG_ 856 TBOXReserChrgEnrgHSC6 20;
BA_ "GenSigStartValue" SG_ 856 TBOXReserChrgEnrgHSC6 62;
BA_ "GenSigPubLatency" SG_ 856 TBOXReserChrgFrqcHSC6 20;
BA_ "GenSigPubLatency" SG_ 856 TBOXReserChrgMdReqHSC6 20;
BA_ "GenSigPubLatency" SG_ 856 TBOXReserChrgRngHSC6 20;
BA_ "GenSigStartValue" SG_ 856 TBOXReserChrgRngHSC6 1022;
BA_ "GenSigPubLatency" SG_ 856 TBOXReserMaxCrntHSC6 20;
BA_ "GenSigStartValue" SG_ 856 TBOXReserMaxCrntHSC6 62;
BA_ "GenSigPubLatency" SG_ 856 TBOXReserTrgtSOCHSC6 20;
BA_ "GenSigStartValue" SG_ 856 TBOXReserTrgtSOCHSC6 1022;
BA_ "GenSigPubLatency" SG_ 1055 network_mode_h6 10;
BA_ "GenSigWriteInterval" SG_ 1055 network_mode_h6 50;
BA_ "GenSigPubLatency" SG_ 1055 signal_config_id_h6 10;
BA_ "GenSigWriteInterval" SG_ 1055 signal_config_id_h6 50;
BA_ "GenSigPubLatency" SG_ 153 TMInvtrCrntHSC6 10;
BA_ "GenSigWriteInterval" SG_ 153 TMInvtrCrntHSC6 100;
BA_ "GenSigStartValue" SG_ 153 TMInvtrCrntHSC6 1024;
BA_ "GenSigPubLatency" SG_ 153 TMInvtrCrntVHSC6 10;
BA_ "GenSigWriteInterval" SG_ 153 TMInvtrCrntVHSC6 100;
BA_ "GenSigStartValue" SG_ 153 TMInvtrCrntVHSC6 1;
BA_ "GenSigPubLatency" SG_ 331 TMInvtrVolHSC6 10;
BA_ "GenSigWriteInterval" SG_ 331 TMInvtrVolHSC6 100;
BA_ "GenSigPubLatency" SG_ 331 TMInvtrVolVHSC6 10;
BA_ "GenSigWriteInterval" SG_ 331 TMInvtrVolVHSC6 100;
BA_ "GenSigPubLatency" SG_ 952 ChargerEfficiencyHSC6 10;
BA_ "GenSigWriteInterval" SG_ 952 ChargerEfficiencyHSC6 100;
BA_ "GenSigPubLatency" SG_ 952 ChargerPFCRelayStatusHSC6 10;
BA_ "GenSigWriteInterval" SG_ 952 ChargerPFCRelayStatusHSC6 100;
BA_ "GenSigPubLatency" SG_ 954 ChargerInsideTemp1HSC6 10;
BA_ "GenSigWriteInterval" SG_ 954 ChargerInsideTemp1HSC6 100;
BA_ "GenSigPubLatency" SG_ 954 ChargerInsideTemp2HSC6 10;
BA_ "GenSigWriteInterval" SG_ 954 ChargerInsideTemp2HSC6 100;
BA_ "GenSigPubLatency" SG_ 954 ChargerOutletTempHSC6 10;
BA_ "GenSigWriteInterval" SG_ 954 ChargerOutletTempHSC6 100;
BA_ "GenSigPubLatency" SG_ 956 ChargerPFCVoltInputHSC6 10;
BA_ "GenSigWriteInterval" SG_ 956 ChargerPFCVoltInputHSC6 100;
BA_ "GenSigPubLatency" SG_ 956 ChargerPFCVoltOutputHSC6 10;
BA_ "GenSigWriteInterval" SG_ 956 ChargerPFCVoltOutputHSC6 100;
BA_ "GenSigPubLatency" SG_ 956 ChrgrFanSpdHSC6 10;
BA_ "GenSigWriteInterval" SG_ 956 ChrgrFanSpdHSC6 100;
BA_ "GenSigPubLatency" SG_ 958 Charger12VUVHSC6 10;
BA_ "GenSigWriteInterval" SG_ 958 Charger12VUVHSC6 100;
BA_ "GenSigPubLatency" SG_ 958 ChargerBatteryReverseHSC6 10;
BA_ "GenSigWriteInterval" SG_ 958 ChargerBatteryReverseHSC6 100;
BA_ "GenSigPubLatency" SG_ 958 ChargerCANMissingHSC6 10;
BA_ "GenSigWriteInterval" SG_ 958 ChargerCANMissingHSC6 100;
BA_ "GenSigPubLatency" SG_ 958 ChargerHVOVHSC6 10;
BA_ "GenSigWriteInterval" SG_ 958 ChargerHVOVHSC6 100;
BA_ "GenSigPubLatency" SG_ 958 ChargerHVUVHSC6 10;
BA_ "GenSigWriteInterval" SG_ 958 ChargerHVUVHSC6 100;
BA_ "GenSigPubLatency" SG_ 958 ChargerInletTempOTPHSC6 10;
BA_ "GenSigWriteInterval" SG_ 958 ChargerInletTempOTPHSC6 100;
BA_ "GenSigPubLatency" SG_ 958 ChargerInsideTemp1OTPHSC6 10;
BA_ "GenSigWriteInterval" SG_ 958 ChargerInsideTemp1OTPHSC6 100;
BA_ "GenSigPubLatency" SG_ 958 ChargerVinUVHSC6 10;
BA_ "GenSigWriteInterval" SG_ 958 ChargerVinUVHSC6 100;
BA_ "GenSigPubLatency" SG_ 958 ChrgrAltCrntLmtHSC6 10;
BA_ "GenSigWriteInterval" SG_ 958 ChrgrAltCrntLmtHSC6 100;
BA_ "GenSigPubLatency" SG_ 958 ChrgrPriySideStwrOverCHSC6 10;
BA_ "GenSigWriteInterval" SG_ 958 ChrgrPriySideStwrOverCHSC6 100;
BA_ "GenSigPubLatency" SG_ 659 BMSChgRelayStatusHSC6 10;
BA_ "GenSigPubLatency" SG_ 659 BMSOffbdChargerPlugOnHSC6 10;
BA_ "GenSigWriteInterval" SG_ 659 BMSOffbdChargerPlugOnHSC6 100;
BA_ "GenSigPubLatency" SG_ 668 ChargerEnableHSC6 10;
BA_ "GenSigWriteInterval" SG_ 668 ChargerEnableHSC6 100;
BA_ "GenSigPubLatency" SG_ 667 BMSVehicleEPOHSC6 10;
BA_ "GenSigWriteInterval" SG_ 667 BMSVehicleEPOHSC6 100;
BA_ "GenSigPubLatency" SG_ 674 BMSClntTem_h6HSC6 10;
BA_ "GenSigStartValue" SG_ 674 BMSClntTem_h6HSC6 255;
BA_ "GenSigPubLatency" SG_ 674 BMSPumpSts_h6HSC6 10;
BA_ "GenSigPubLatency" SG_ 939 BMSOnbdChrgEnrgV_h6HSC6 10;
BA_ "GenSigWriteInterval" SG_ 939 BMSOnbdChrgEnrgV_h6HSC6 100;
BA_ "GenSigPubLatency" SG_ 939 BMSOnbdChrgEnrg_h6HSC6 10;
BA_ "GenSigWriteInterval" SG_ 939 BMSOnbdChrgEnrg_h6HSC6 100;
BA_ "GenSigStartValue" SG_ 939 BMSOnbdChrgEnrg_h6HSC6 1048575;
BA_ "GenSigPubLatency" SG_ 939 BMSPwrEfncyV_h6HSC6 10;
BA_ "GenSigWriteInterval" SG_ 939 BMSPwrEfncyV_h6HSC6 100;
BA_ "GenSigPubLatency" SG_ 939 BMSPwrEfncy_h6HSC6 10;
BA_ "GenSigWriteInterval" SG_ 939 BMSPwrEfncy_h6HSC6 100;
BA_ "GenSigStartValue" SG_ 939 BMSPwrEfncy_h6HSC6 255;
BA_ "GenSigPubLatency" SG_ 930 HVDCDCHVSideVolHSC6 10;
BA_ "GenSigWriteInterval" SG_ 930 HVDCDCHVSideVolHSC6 100;
BA_ "GenSigPubLatency" SG_ 930 HVDCDCHVSideVolVHSC6 10;
BA_ "GenSigWriteInterval" SG_ 930 HVDCDCHVSideVolVHSC6 100;
BA_ "GenSigStartValue" SG_ 930 HVDCDCHVSideVolVHSC6 1;
BA_ "GenSigPubLatency" SG_ 150 ISGInvtrCrntHSC6 10;
BA_ "GenSigWriteInterval" SG_ 150 ISGInvtrCrntHSC6 100;
BA_ "GenSigStartValue" SG_ 150 ISGInvtrCrntHSC6 1024;
BA_ "GenSigPubLatency" SG_ 150 ISGInvtrCrntVHSC6 10;
BA_ "GenSigWriteInterval" SG_ 150 ISGInvtrCrntVHSC6 100;
BA_ "GenSigStartValue" SG_ 150 ISGInvtrCrntVHSC6 1;
BA_ "GenSigPubLatency" SG_ 1053 TelmcsLclCalendarDayHSC6 20;
BA_ "GenSigPubLatency" SG_ 1053 TelmcsLclCalendarMonthHSC6 20;
BA_ "GenSigPubLatency" SG_ 1053 TelmcsLclCalendarYearHSC6 20;
BA_ "GenSigPubLatency" SG_ 1053 TelmcsLclHourOfDayHSC6 20;
BA_ "GenSigPubLatency" SG_ 1053 TelmcsLclMinuteOfHourHSC6 20;
BA_ "GenSigPubLatency" SG_ 1053 TelmcsLclSecsOfMinuteHSC6 20;
VAL_ 952 ChargerACCurrentHSC6 255 "fail" ;
VAL_ 952 ChargerACVoltHSC6 255 "fail" ;
VAL_ 952 ChargerFanStatusHSC6 2 "failure" 1 "closed" 0 "open" ;
VAL_ 952 ChargerHVCurrentHSC6 1023 "fail" ;
VAL_ 952 ChargerHVRelayStatusHSC6 2 "failure" 1 "closed" 0 "open" ;
VAL_ 952 ChargerHVVoltHSC6 32767 "fail" ;
VAL_ 952 ChargerStatusHSC6 10 "Stop" 9 "Fault" 7 "Warning" 5 "Charging" 3 "Ready" 1 "Powerup" 0 "idle" ;
VAL_ 952 ChargerWakeUpHSC6 1 "TRUE" 0 "FALSE" ;
VAL_ 956 ChargerLVCurrentHSC6 255 "fail" ;
VAL_ 956 ChargerLVVoltHSC6 255 "fail" ;
VAL_ 958 BMSCellTemVHSC6 1 "Invalid" 0 "Valid" ;
VAL_ 958 BMSCellVolVHSC6 1 "Invalid" 0 "Valid" ;
VAL_ 659 BMSBalancingDoneHSC6 1 "TRUE" 0 "FALSE" ;
VAL_ 659 BMSBalancingStatusHSC6 1 "TRUE" 0 "FALSE" ;
VAL_ 659 BMSCellBalancingCountHSC6 255 "Error" 254 "Init" ;
VAL_ 659 BMSCellOverVoltHSC6 1 "TRUE" 0 "FALSE" ;
VAL_ 659 BMSCellUnderVoltHSC6 1 "TRUE" 0 "FALSE" ;
VAL_ 659 BMSContactorPowerCmdHSC6 1 "on" 0 "off" ;
VAL_ 659 BMSContactorPowerMonHSC6 1 "on" 0 "off" ;
VAL_ 659 BMSCrashCircuitStatusHSC6 1 "Open" 0 "Closed" ;
VAL_ 659 BMSEEpromWipHSC6 1 "TRUE" 0 "FALSE" ;
VAL_ 659 BMSLVBatInputHSC6 255 "Error" 254 "Init" ;
VAL_ 659 BMSModuleEnableHSC6 1 "TRUE" 0 "FALSE" ;
VAL_ 659 BMSNegRelayStatusHSC6 2 "failure" 1 "closed" 0 "open" ;
VAL_ 659 BMSOffbdChargerWakeupHSC6 1 "active" 0 "not active" ;
VAL_ 659 BMSOnbdChargerWakeupHSC6 1 "active" 0 "not active" ;
VAL_ 659 BMSPosRelayStatusHSC6 2 "failure" 1 "closed" 0 "open" ;
VAL_ 659 BMSPreRelayStatusHSC6 2 "failure" 1 "closed" 0 "open" ;
VAL_ 659 BMSPTIsolationLevelHSC6 3 "Isolation EPO" 2 "Isolation Alarm" 1 "Isolation Warning" 0 "Isolation OK" ;
VAL_ 659 BMSReadyHSC6 1 "TRUE" 0 "FALSE" ;
VAL_ 659 BMSRelayStepHSC6 12 "main PN closed" 11 "main PN closed DRIVE" 10 "failed mainP open  " 9 "open mainR" 8 "close mainP " 7 "wait precharge" 6 "failed mainN open" 5 "close mainN" 4 "failed mainN weld" 3 "failed mainR open" 2 "close mainR" 1 "failed mainP or R welded" 0 "all open" ;
VAL_ 659 BMSVehicleWakeupHSC6 1 "active" 0 "not active" ;
VAL_ 661 BMSPackCrntV_h6HSC6 1 "Invalid" 0 "Valid" ;
VAL_ 661 BMSPackSOCV_h6HSC6 1 "Invalid" 0 "Valid" ;
VAL_ 661 BMSPackVolV_h6HSC6 1 "Invalid" 0 "Valid" ;
VAL_ 663 BMSBscStaHSC6 20 "Wireless Pre-charging" 19 "Wireless Charging Done" 18 "Wireless Charging Mode" 17 "Wireless Charge Ready" 16 "Off-board Pre-charging" 15 "Fault" 14 "Balancing" 13 "Collision Mode" 12 "On-board Pre-charging" 10 "On-board Charging Done" 9 "Off-board Charging Done" 8 "Offline Balance" 7 "Off-board Charging Mode" 6 "On-board Charging Mode" 5 "Off-board Charge Ready" 4 "On-board Charge Ready" 3 "Drive Mode" 2 "Drive Pre-charging" 1 "Drive Ready" 0 "Power Up" ;
VAL_ 663 BMSFltLvlHSC6 5 "Hard EPO" 4 "Soft EPO" 3 "Alarm2" 2 "Alarm1" 1 "Warning" 0 "None" ;
VAL_ 663 BMSHVILClsdHSC6 1 "True" 0 "False" ;
VAL_ 663 BMSMainRelaySts_h6HSC6 3 "Failure" 2 "Partly Closed" 1 "All Closed" 0 "All Open" ;
VAL_ 663 BMSOfbdChrgRelayStsHSC6 2 "failure" 1 "closed" 0 "open" ;
VAL_ 663 BMSOnbdChrgRelayStsHSC6 2 "failure" 1 "closed" 0 "open" ;
VAL_ 663 BMSPtIsltnRstcVHSC6 1 "Invalid" 0 "Valid" ;
VAL_ 663 BMSVehEmgcPwrOffHSC6 14 "init" 8 "OCWhileCharge" 7 "OCWhileDischarge" 6 "HVBuserror" 5 "CloseCmdError" 4 "OCWhilePowerDown" 3 "CrashCircuitOpen" 2 "VehCANMissing" 1 "LVBatterylow" ;
VAL_ 663 OffbdChrgrSysKeepAwkHSC6 1 "TRUE" 0 "FALSE" ;
VAL_ 663 OnbdChrgrSktEleccLckEHSC6 1 "TRUE" 0 "FALSE" ;
VAL_ 663 OnbdChrgrSysKeepAwkHSC6 1 "TRUE" 0 "FALSE" ;
VAL_ 369 BMSChrgCrntLmtVHSC6 1 "Invalid" 0 "Valid" ;
VAL_ 369 BMSDschrgCrntLmtVHSC6 1 "Invalid" 0 "Valid" ;
VAL_ 369 BMSMaxVolLmtVHSC6 1 "Invalid" 0 "Valid" ;
VAL_ 369 BMSMinVolLmtVHSC6 1 "Invalid" 0 "Valid" ;
VAL_ 668 ChargeCurrentHSC6 1023 "fail" ;
VAL_ 668 ChargePowerHSC6 255 "fail" ;
VAL_ 668 ChargerCapacityHSC6 255 "fail" ;
VAL_ 668 ChargerModeHSC6 3 "power control mode" 2 "voltage control mode" 1 "current control mode" 0 "Invalid" ;
VAL_ 665 BMSFlameGasStatusHSC6 255 "Error" 254 "Init" ;
VAL_ 665 BMSNegativeBusVoltHSC6 4095 "Error" 4094 "Init" ;
VAL_ 665 BMSPackCurrent2HSC6 65535 "Error" 65534 "Init" ;
VAL_ 665 BMSPackSOCActualHSC6 255 "Error" 254 "Init" ;
VAL_ 665 BMSPositiveBusVoltHSC6 4095 "Error" 4094 "Init" ;
VAL_ 667 BMSBusbarTempMaxHSC6 255 "Error" 254 "Init" ;
VAL_ 667 BMSChgIngDriverStatHSC6 1 "closed" 0 "open" ;
VAL_ 667 BMSChrgrPlugCnctnIO_h6HSC6 1 "Lamp Off" 0 "Lamp On" ;
VAL_ 667 BMSChrgStsIO_h6HSC6 1 "Lamp Off" 0 "Lamp On" ;
VAL_ 667 BMSConIndDriverStatHSC6 1 "Open" 0 "Closed" ;
VAL_ 667 BMSLiquidSensorStHSC6 3 "OOR High" 2 "OOR Low" 1 "Fault" 0 "OK" ;
VAL_ 667 BMSPackSOHHSC6 1023 "Error" 1022 "Init" ;
VAL_ 667 BMSStaOfHealthCapctHSC6 255 "Error" 254 "Init" ;
VAL_ 667 BMSStaOfHealthResiHSC6 255 "Error" 254 "Init" ;
VAL_ 1100 keep_network_BMSHSC6 1 "keep network request" 0 "no keep network request" ;
VAL_ 370 BMSChrgPeakPwrVHSC6 1 "Invalid" 0 "Valid" ;
VAL_ 370 BMSChrgPwrLmtVHSC6 1 "Invalid" 0 "Valid" ;
VAL_ 370 BMSDschrgPeakPwrVHSC6 1 "Invalid" 0 "Valid" ;
VAL_ 370 BMSDschrgPwrLmtVHSC6 1 "Invalid" 0 "Valid" ;
VAL_ 371 BMSCellMaxVolVHSC6 1 "Invalid" 0 "Valid" ;
VAL_ 371 BMSCellMinVolVHSC6 1 "Invalid" 0 "Valid" ;
VAL_ 371 BMSChrgBufVHSC6 1 "Invalid" 0 "Valid" ;
VAL_ 371 BMSDschrgBufVHSC6 1 "Invalid" 0 "Valid" ;
VAL_ 674 BMSCellMaxTemV_h6HSC6 1 "Invalid" 0 "Valid" ;
VAL_ 674 BMSCellMinTemV_h6HSC6 1 "Invalid" 0 "Valid" ;
VAL_ 674 BMSChrgReqHSC6 2 "Charge Fault" 1 "Charge Request" 0 "No Charge Request" ;
VAL_ 674 BMSOfbdChrgrPlugOnHSC6 1 "TRUE" 0 "FALSE" ;
VAL_ 674 BMSOnbdChrgrPlugOn_h6HSC6 1 "TRUE" 0 "FALSE" ;
VAL_ 913 BMSChrgSts_h6HSC6 5 "Reserved" 4 "Charge Fault" 3 "Balancing" 2 "Charge Done" 1 "Charging" 0 "None" ;
VAL_ 913 BMSReserPushItemHSC6 6 "Reserved" 5 "Charging Complete" 4 "Charging Start" 3 "Charge Cease" 2 "Charging Fault" 1 "Charging Gun Not Plug In" 0 "None" ;
VAL_ 915 BMSReserChrgCtrlDspCmdHSC6 4 "Reserved" 3 "Command Execute Failed" 2 "Command Execute Success" 1 "Command Accept" 0 "None" ;
VAL_ 915 BMSReserChrgFltReasonHSC6 4096 "Reserved" 2048 "Voltage Mismatch" 1024 "Current Mismatch" 512 "Voltage Low" 256 "Voltage High" 128 "Current Low" 64 "Current High" 32 "Temperature Low" 16 "Temperature High" 8 "Communication Fault" 4 "Isolation Fault" 2 "HVIL open" 1 "Reservation Failed" 0 "None" ;
VAL_ 915 BMSReserChrgFrqcDspCmdHSC6 3 "Reserved" 2 "Daily" 1 "Once" 0 "None" ;
VAL_ 915 BMSReserChrgMdDspCmd_h6HSC6 4 "Soc Based Mode" 3 "Range Based Mode" 2 "Energy Based Mode" 1 "Time Based Mode" 0 "Unavailable" ;
VAL_ 915 BMSReserChrgRespVHSC6 1 "Invalid" 0 "Valid" ;
VAL_ 915 BMSReserFltReasonHSC6 4 "Reserved" 3 "Operation Error" 2 "BMS Set RTC Failed" 1 "EEPROM Storage Failed" 0 "None" ;
VAL_ 915 BMSReserStaDspCmdHSC6 3 "Reserved" 2 "Reservation Switch Off" 1 "Reservation Switch On" 0 "None" ;
VAL_ 936 ChrgngRmnngTimeV_h6HSC6 1 "Invalid" 0 "Valid" ;
VAL_ 1091 wake_network_BMSHSC6 1 "wake-up network request" 0 "no wake-up network request" ;
VAL_ 916 EPTChrgCoolngSysStsHSC6 2 "Cooling system Unable" 1 "Cooling system Limited" 0 "Cooling system Normal" ;
VAL_ 916 OfbdChrgrNgtvSktTemVHSC6 1 "Invalid" 0 "Valid" ;
VAL_ 916 OfbdChrgrPstvSktTemVHSC6 1 "Invalid" 0 "Valid" ;
VAL_ 916 OnbdChrgrSktEleccLckSHSC6 3 "Electronic Lock Feedback Error" 2 "Electronic Lock Control Line Failure" 1 "Locked" 0 "Unlocked" ;
VAL_ 138 EPTHVBatPwrRlseReqHSC6 1 "request" 0 "no request" ;
VAL_ 138 EPTHVEmgcPwrOffReqHSC6 1 "request" 0 "no request" ;
VAL_ 138 EPTMainRelayDrvReqHSC6 3 "Reserved" 2 "Close Fast Charge Relay" 1 "Close Main Relay" 0 "Open Request" ;
VAL_ 854 TBOXReserStMonthHSC6 12 "December" 11 "November" 10 "October" 9 "September" 8 "August" 7 "July" 6 "June" 5 "May" 4 "April" 3 "March" 2 "February" 1 "January" 0 "Unknown" ;
VAL_ 856 TBOXReserChrgCtrlReqHSC6 5 "Reserved" 4 "Stop Charge" 3 "Start Charge" 2 "Reservation Switch Off" 1 "Reservation Switch On" 0 "None" ;
VAL_ 856 TBOXReserChrgFrqcHSC6 3 "Reserved" 2 "Daily" 1 "Once" 0 "None" ;
VAL_ 856 TBOXReserChrgMdReqHSC6 4 "Soc Based Mode" 3 "Range Based Mode" 2 "Energy Based Mode" 1 "Time Based Mode" 0 "None" ;
VAL_ 1055 network_mode_h6 2 "normal" 1 "shutdown" 0 "start-up" ;
VAL_ 1055 signal_config_id_h6 8272 "config: NMC/OTS2/base" ;
VAL_ 153 TMInvtrCrntVHSC6 1 "Invalid" 0 "Valid" ;
VAL_ 952 ChargerEfficiencyHSC6 255 "Error" ;
VAL_ 952 ChargerPFCRelayStatusHSC6 2 "failure" 1 "closed" 0 "open" ;
VAL_ 954 ChargerInsideTemp1HSC6 255 "fail" ;
VAL_ 954 ChargerInsideTemp2HSC6 255 "fail" ;
VAL_ 954 ChargerOutletTempHSC6 255 "fail" ;
VAL_ 956 ChargerPFCVoltInputHSC6 32767 "Fail" ;
VAL_ 956 ChargerPFCVoltOutputHSC6 32767 "Fail" ;
VAL_ 958 Charger12VUVHSC6 1 "TRUE" 0 "FALSE" ;
VAL_ 958 ChargerBatteryReverseHSC6 1 "TRUE" 0 "FALSE" ;
VAL_ 958 ChargerCANMissingHSC6 1 "TRUE" 0 "FALSE" ;
VAL_ 958 ChargerHVOVHSC6 1 "TRUE" 0 "FALSE" ;
VAL_ 958 ChargerHVUVHSC6 1 "TRUE" 0 "FALSE" ;
VAL_ 958 ChargerInletTempOTPHSC6 1 "TRUE" 0 "FALSE" ;
VAL_ 958 ChargerInsideTemp1OTPHSC6 1 "TRUE" 0 "FALSE" ;
VAL_ 958 ChargerVinUVHSC6 1 "TRUE" 0 "FALSE" ;
VAL_ 958 ChrgrAltCrntLmtHSC6 255 "Fail" ;
VAL_ 958 ChrgrPriySideStwrOverCHSC6 1 "TRUE" 0 "FALSE" ;
VAL_ 659 BMSChgRelayStatusHSC6 2 "failure" 1 "closed" 0 "open" ;
VAL_ 659 BMSOffbdChargerPlugOnHSC6 1 "TRUE" 0 "FALSE" ;
VAL_ 668 ChargerEnableHSC6 1 "Enable" 0 "Disable" ;
VAL_ 667 BMSVehicleEPOHSC6 14 "Init" 8 "OCWhileCharge" 7 "OCWhileDischarge" 6 "HVBusError" 5 "CloseCmdError" 4 "OCWhilePowerDown" 3 "CrashCircuitOpen" 2 "VehCANMissing" 1 "LVBatterylow" ;
VAL_ 674 BMSPumpSts_h6HSC6 3 "Failed High" 2 "Failed Low" 1 "On" 0 "OFF" ;
VAL_ 939 BMSOnbdChrgEnrgV_h6HSC6 1 "Invalid" 0 "Valid" ;
VAL_ 939 BMSOnbdChrgEnrg_h6HSC6 1048575 "Error" 1048574 "Init" ;
VAL_ 939 BMSPwrEfncyV_h6HSC6 1 "Invalid" 0 "Valid" ;
VAL_ 939 BMSPwrEfncy_h6HSC6 255 "Error" 254 "Init" ;
VAL_ 930 HVDCDCHVSideVolVHSC6 1 "Invalid" 0 "Valid" ;
VAL_ 150 ISGInvtrCrntVHSC6 1 "Invalid" 0 "Valid" ;
VAL_ 1053 TelmcsLclCalendarMonthHSC6 15 "Reserved" 14 "Reserved" 13 "Reserved" 12 "December" 11 "November" 10 "October" 9 "September" 8 "August" 7 "July" 6 "June" 5 "May" 4 "April" 3 "March" 2 "February" 1 "January" 0 "Unknown" ;
